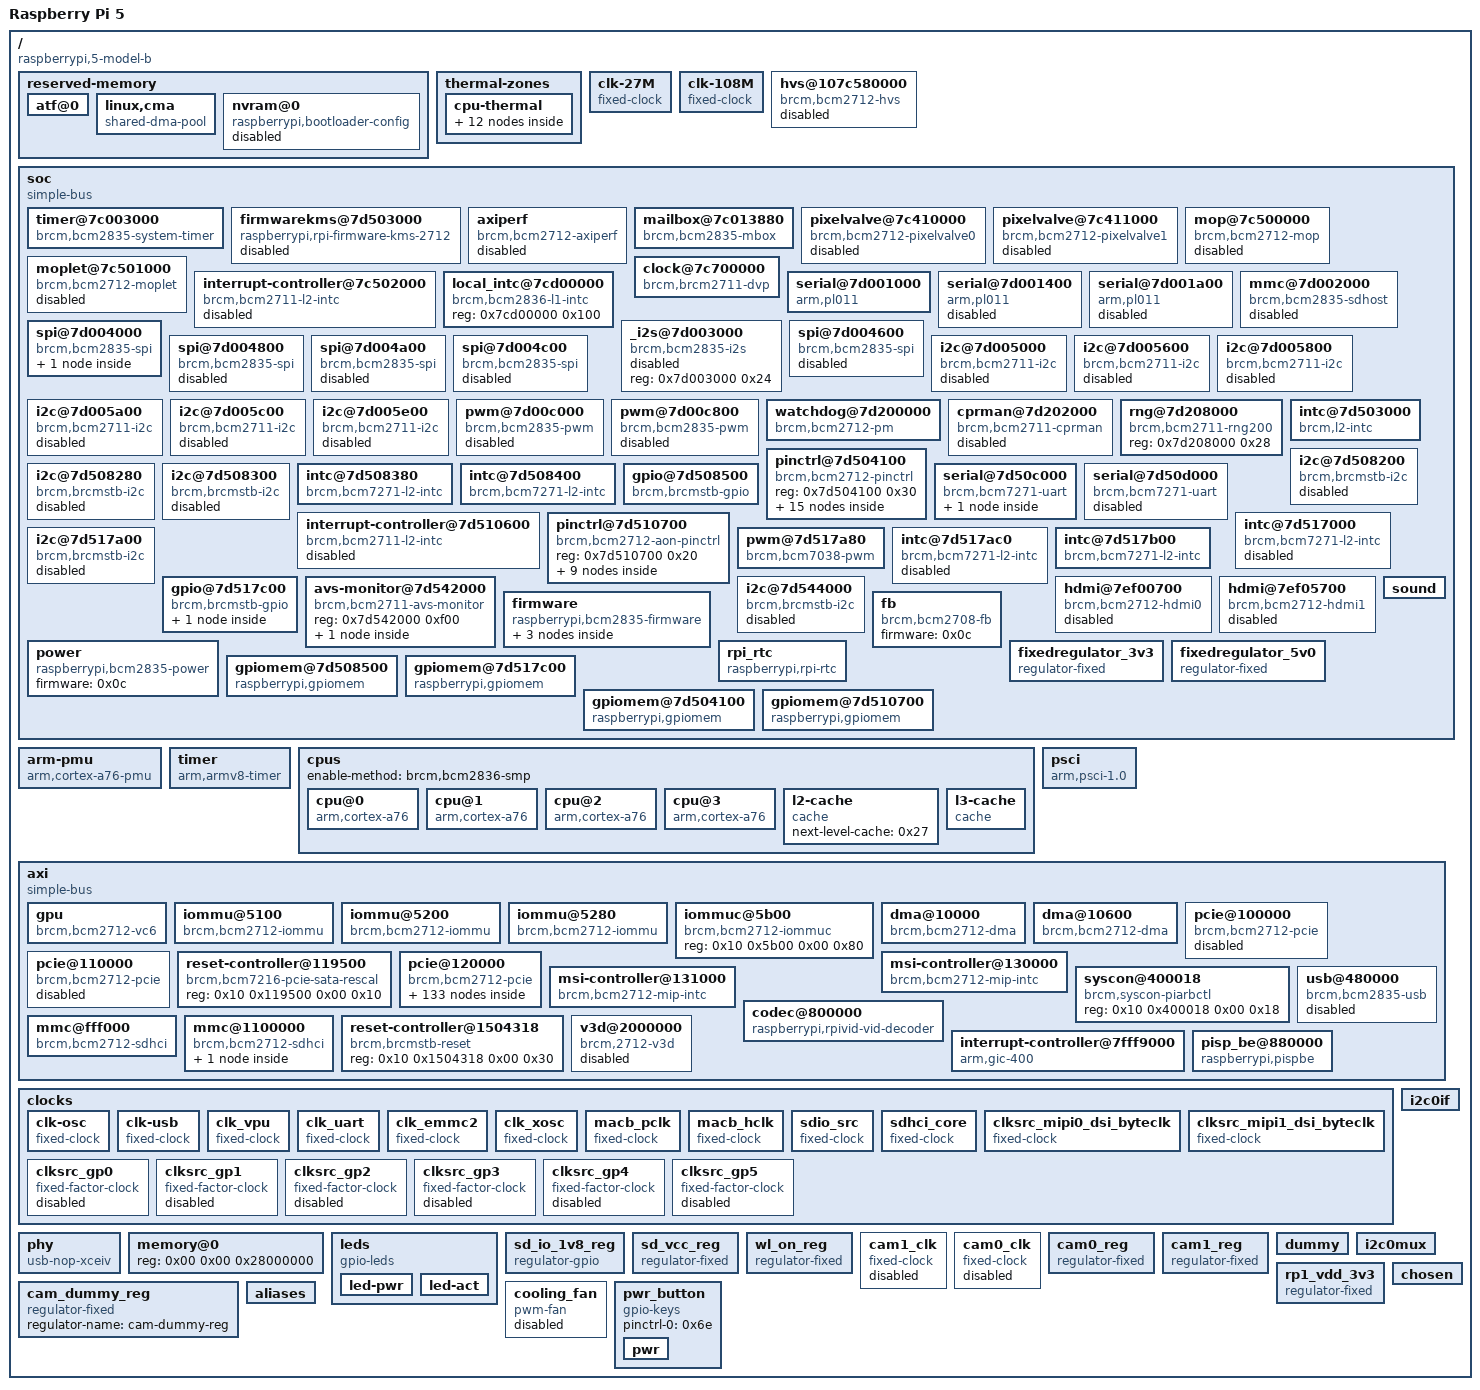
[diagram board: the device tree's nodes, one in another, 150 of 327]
/dts-v1/;

/ {
	compatible = "raspberrypi,5-model-b\0brcm,bcm2712";
	model = "Raspberry Pi 5";
	#address-cells = <0x02>;
	#size-cells = <0x01>;
	interrupt-parent = <0x01>;

	reserved-memory {
		#address-cells = <0x02>;
		#size-cells = <0x01>;
		ranges;
		phandle = <0x6f>;

		atf@0 {
			reg = <0x00 0x00 0x80000>;
			no-map;
		};

		linux,cma {
			compatible = "shared-dma-pool";
			size = <0x4000000>;
			reusable;
			linux,cma-default;
			alloc-ranges = <0x00 0x00 0x40000000>;
			phandle = <0x70>;
		};

		nvram@0 {
			compatible = "raspberrypi,bootloader-config\0nvmem-rmem";
			#address-cells = <0x01>;
			#size-cells = <0x01>;
			reg = <0x00 0x00 0x00>;
			no-map;
			status = "disabled";
			phandle = <0x71>;
		};
	};

	thermal-zones {

		cpu-thermal {
			polling-delay-passive = <0x7d0>;
			polling-delay = <0x3e8>;
			coefficients = <0xfffffdda 0x6ddd0>;
			thermal-sensors = <0x02>;
			phandle = <0x72>;

			trips {
				phandle = <0x73>;

				cpu-crit {
					temperature = <0x1adb0>;
					hysteresis = <0x00>;
					type = "critical";
					phandle = <0x08>;
				};

				cpu-tepid {
					temperature = <0xc350>;
					hysteresis = <0x1388>;
					type = "active";
					phandle = <0x03>;
				};

				cpu-warm {
					temperature = <0xea60>;
					hysteresis = <0x1388>;
					type = "active";
					phandle = <0x05>;
				};

				cpu-hot {
					temperature = <0x107ac>;
					hysteresis = <0x1388>;
					type = "active";
					phandle = <0x06>;
				};

				cpu-vhot {
					temperature = <0x124f8>;
					hysteresis = <0x1388>;
					type = "active";
					phandle = <0x07>;
				};
			};

			cooling-maps {
				phandle = <0x74>;

				tepid {
					trip = <0x03>;
					cooling-device = <0x04 0x01 0x01>;
				};

				warm {
					trip = <0x05>;
					cooling-device = <0x04 0x02 0x02>;
				};

				hot {
					trip = <0x06>;
					cooling-device = <0x04 0x03 0x03>;
				};

				vhot {
					trip = <0x07>;
					cooling-device = <0x04 0x04 0x04>;
				};

				melt {
					trip = <0x08>;
					cooling-device = <0x04 0x04 0x04>;
				};
			};
		};
	};

	clk-27M {
		#clock-cells = <0x00>;
		compatible = "fixed-clock";
		clock-frequency = <0x19bfcc0>;
		clock-output-names = "27MHz-clock";
		phandle = <0x1b>;
	};

	clk-108M {
		#clock-cells = <0x00>;
		compatible = "fixed-clock";
		clock-frequency = <0x66ff300>;
		clock-output-names = "108MHz-clock";
		phandle = <0x0d>;
	};

	hvs@107c580000 {
		compatible = "brcm,bcm2712-hvs";
		reg = <0x10 0x7c580000 0x1a000>;
		interrupt-parent = <0x09>;
		interrupts = <0x02 0x09 0x10>;
		interrupt-names = "ch0-eof\0ch1-eof\0ch2-eof";
		status = "disabled";
		clocks = <0x0a 0x04 0x0a 0x10>;
		clock-names = "core\0disp";
		phandle = <0x75>;
	};

	soc {
		compatible = "simple-bus";
		#address-cells = <0x01>;
		#size-cells = <0x01>;
		ranges = <0x7c000000 0x10 0x7c000000 0x4000000>;
		dma-ranges = <0xc0000000 0x00 0x00 0x40000000 0x7c000000 0x10 0x7c000000 0x4000000>;
		phandle = <0x76>;

		timer@7c003000 {
			compatible = "brcm,bcm2835-system-timer";
			reg = <0x7c003000 0x1000>;
			interrupts = <0x00 0x40 0x04 0x00 0x41 0x04 0x00 0x42 0x04 0x00 0x43 0x04>;
			clock-frequency = <0xf4240>;
			phandle = <0x77>;
		};

		firmwarekms@7d503000 {
			compatible = "raspberrypi,rpi-firmware-kms-2712";
			reg = <0x7d503000 0x18>;
			interrupt-parent = <0x0b>;
			interrupts = <0x13>;
			brcm,firmware = <0x0c>;
			status = "disabled";
			phandle = <0x78>;
		};

		axiperf {
			compatible = "brcm,bcm2712-axiperf";
			reg = <0x7c012800 0x100 0x7e000000 0x100>;
			firmware = <0x0c>;
			status = "disabled";
			phandle = <0x5d>;
		};

		mailbox@7c013880 {
			compatible = "brcm,bcm2835-mbox";
			reg = <0x7c013880 0x40>;
			interrupts = <0x00 0x21 0x04>;
			#mbox-cells = <0x00>;
			phandle = <0x21>;
		};

		pixelvalve@7c410000 {
			compatible = "brcm,bcm2712-pixelvalve0";
			reg = <0x7c410000 0x100>;
			interrupts = <0x00 0x65 0x04>;
			status = "disabled";
			phandle = <0x79>;
		};

		pixelvalve@7c411000 {
			compatible = "brcm,bcm2712-pixelvalve1";
			reg = <0x7c411000 0x100>;
			interrupts = <0x00 0x6e 0x04>;
			status = "disabled";
			phandle = <0x7a>;
		};

		mop@7c500000 {
			compatible = "brcm,bcm2712-mop";
			reg = <0x7c500000 0x28>;
			interrupt-parent = <0x09>;
			interrupts = <0x01>;
			status = "disabled";
			phandle = <0x7b>;
		};

		moplet@7c501000 {
			compatible = "brcm,bcm2712-moplet";
			reg = <0x7c501000 0x20>;
			interrupt-parent = <0x09>;
			interrupts = <0x00>;
			status = "disabled";
			phandle = <0x7c>;
		};

		interrupt-controller@7c502000 {
			compatible = "brcm,bcm2711-l2-intc\0brcm,l2-intc";
			reg = <0x7c502000 0x30>;
			interrupts = <0x00 0x61 0x04>;
			interrupt-controller;
			#interrupt-cells = <0x01>;
			status = "disabled";
			phandle = <0x09>;
		};

		clock@7c700000 {
			compatible = "brcm,brcm2711-dvp";
			reg = <0x7c700000 0x10>;
			clocks = <0x0d>;
			#clock-cells = <0x01>;
			#reset-cells = <0x01>;
			phandle = <0x1d>;
		};

		local_intc@7cd00000 {
			compatible = "brcm,bcm2836-l1-intc";
			reg = <0x7cd00000 0x100>;
			phandle = <0x7d>;
		};

		serial@7d001000 {
			compatible = "arm,pl011\0arm,primecell";
			reg = <0x7d001000 0x200>;
			interrupts = <0x00 0x79 0x04>;
			clocks = <0x0e 0x0f>;
			clock-names = "uartclk\0apb_pclk";
			arm,primecell-periphid = <0x241011>;
			status = "okay";
			phandle = <0x7e>;
		};

		serial@7d001400 {
			compatible = "arm,pl011\0arm,primecell";
			reg = <0x7d001400 0x200>;
			interrupts = <0x00 0x79 0x04>;
			clocks = <0x0e 0x0f>;
			clock-names = "uartclk\0apb_pclk";
			arm,primecell-periphid = <0x241011>;
			status = "disabled";
			phandle = <0x7f>;
		};

		serial@7d001a00 {
			compatible = "arm,pl011\0arm,primecell";
			reg = <0x7d001a00 0x200>;
			interrupts = <0x00 0x79 0x04>;
			clocks = <0x0e 0x0f>;
			clock-names = "uartclk\0apb_pclk";
			arm,primecell-periphid = <0x241011>;
			status = "disabled";
			phandle = <0x80>;
		};

		mmc@7d002000 {
			compatible = "brcm,bcm2835-sdhost";
			reg = <0x7d002000 0x100>;
			clocks = <0x0f>;
			status = "disabled";
			phandle = <0x81>;
		};

		_i2s@7d003000 {
			compatible = "brcm,bcm2835-i2s";
			reg = <0x7d003000 0x24>;
			status = "disabled";
			phandle = <0x82>;
		};

		spi@7d004000 {
			compatible = "brcm,bcm2835-spi";
			reg = <0x7d004000 0x200>;
			interrupts = <0x00 0x76 0x04>;
			clocks = <0x0f>;
			num-cs = <0x01>;
			#address-cells = <0x01>;
			#size-cells = <0x00>;
			status = "okay";
			dmas = <0x10 0x06 0x10 0x07>;
			dma-names = "tx\0rx";
			pinctrl-names = "default";
			cs-gpios = <0x11 0x01 0x01>;
			pinctrl-0 = <0x12 0x13>;
			phandle = <0x83>;

			spidev@0 {
				compatible = "spidev";
				reg = <0x00>;
				#address-cells = <0x01>;
				#size-cells = <0x00>;
				spi-max-frequency = <0x1312d00>;
				status = "okay";
				phandle = <0x84>;
			};
		};

		spi@7d004600 {
			compatible = "brcm,bcm2835-spi";
			reg = <0x7d004600 0x200>;
			interrupts = <0x00 0x76 0x04>;
			clocks = <0x0f>;
			#address-cells = <0x01>;
			#size-cells = <0x00>;
			status = "disabled";
			phandle = <0x85>;
		};

		spi@7d004800 {
			compatible = "brcm,bcm2835-spi";
			reg = <0x7d004800 0x200>;
			interrupts = <0x00 0x76 0x04>;
			clocks = <0x0f>;
			#address-cells = <0x01>;
			#size-cells = <0x00>;
			status = "disabled";
			phandle = <0x86>;
		};

		spi@7d004a00 {
			compatible = "brcm,bcm2835-spi";
			reg = <0x7d004a00 0x200>;
			interrupts = <0x00 0x76 0x04>;
			clocks = <0x0f>;
			#address-cells = <0x01>;
			#size-cells = <0x00>;
			status = "disabled";
			phandle = <0x87>;
		};

		spi@7d004c00 {
			compatible = "brcm,bcm2835-spi";
			reg = <0x7d004c00 0x200>;
			interrupts = <0x00 0x76 0x04>;
			clocks = <0x0f>;
			#address-cells = <0x01>;
			#size-cells = <0x00>;
			status = "disabled";
			phandle = <0x88>;
		};

		i2c@7d005000 {
			compatible = "brcm,bcm2711-i2c\0brcm,bcm2835-i2c";
			reg = <0x7d005000 0x20>;
			interrupts = <0x00 0x75 0x04>;
			clocks = <0x0f>;
			#address-cells = <0x01>;
			#size-cells = <0x00>;
			status = "disabled";
			phandle = <0x89>;
		};

		i2c@7d005600 {
			compatible = "brcm,bcm2711-i2c\0brcm,bcm2835-i2c";
			reg = <0x7d005600 0x20>;
			interrupts = <0x00 0x75 0x04>;
			clocks = <0x0f>;
			#address-cells = <0x01>;
			#size-cells = <0x00>;
			status = "disabled";
			clock-frequency = <0x61a80>;
			pinctrl-0 = <0x14>;
			pinctrl-names = "default";
			phandle = <0x8a>;
		};

		i2c@7d005800 {
			compatible = "brcm,bcm2711-i2c\0brcm,bcm2835-i2c";
			reg = <0x7d005800 0x20>;
			interrupts = <0x00 0x75 0x04>;
			clocks = <0x0f>;
			#address-cells = <0x01>;
			#size-cells = <0x00>;
			status = "disabled";
			phandle = <0x8b>;
		};

		i2c@7d005a00 {
			compatible = "brcm,bcm2711-i2c\0brcm,bcm2835-i2c";
			reg = <0x7d005a00 0x20>;
			interrupts = <0x00 0x75 0x04>;
			clocks = <0x0f>;
			#address-cells = <0x01>;
			#size-cells = <0x00>;
			status = "disabled";
			phandle = <0x8c>;
		};

		i2c@7d005c00 {
			compatible = "brcm,bcm2711-i2c\0brcm,bcm2835-i2c";
			reg = <0x7d005c00 0x20>;
			interrupts = <0x00 0x75 0x04>;
			clocks = <0x0f>;
			#address-cells = <0x01>;
			#size-cells = <0x00>;
			status = "disabled";
			phandle = <0x8d>;
		};

		i2c@7d005e00 {
			compatible = "brcm,bcm2711-i2c\0brcm,bcm2835-i2c";
			reg = <0x7d005e00 0x20>;
			interrupts = <0x00 0x75 0x04>;
			clocks = <0x0f>;
			#address-cells = <0x01>;
			#size-cells = <0x00>;
			status = "disabled";
			phandle = <0x8e>;
		};

		pwm@7d00c000 {
			compatible = "brcm,bcm2835-pwm";
			reg = <0x7d00c000 0x28>;
			assigned-clock-rates = <0x989680>;
			#pwm-cells = <0x03>;
			status = "disabled";
			phandle = <0x8f>;
		};

		pwm@7d00c800 {
			compatible = "brcm,bcm2835-pwm";
			reg = <0x7d00c800 0x28>;
			assigned-clock-rates = <0x989680>;
			#pwm-cells = <0x03>;
			status = "disabled";
			phandle = <0x90>;
		};

		watchdog@7d200000 {
			compatible = "brcm,bcm2712-pm";
			reg = <0x7d200000 0x308>;
			reg-names = "pm";
			#power-domain-cells = <0x01>;
			#reset-cells = <0x01>;
			clock-names = "v3d\0peri_image\0h264\0isp";
			system-power-controller;
			phandle = <0x5b>;
		};

		cprman@7d202000 {
			compatible = "brcm,bcm2711-cprman";
			reg = <0x7d202000 0x2000>;
			#clock-cells = <0x01>;
			clocks = <0x15>;
			status = "disabled";
			phandle = <0x91>;
		};

		rng@7d208000 {
			compatible = "brcm,bcm2711-rng200";
			reg = <0x7d208000 0x28>;
			status = "okay";
			phandle = <0x68>;
		};

		intc@7d503000 {
			compatible = "brcm,l2-intc";
			reg = <0x7d503000 0x18>;
			interrupts = <0x00 0xee 0x04>;
			interrupt-controller;
			#interrupt-cells = <0x01>;
			phandle = <0x0b>;
		};

		pinctrl@7d504100 {
			compatible = "brcm,bcm2712-pinctrl";
			reg = <0x7d504100 0x30>;
			phandle = <0x92>;

			uarta_24_pins {
				phandle = <0x18>;

				pin_rts {
					function = "uart0";
					pins = "gpio24";
					bias-disable;
				};

				pin_cts {
					function = "uart0";
					pins = "gpio25";
					bias-pull-up;
				};

				pin_txd {
					function = "uart0";
					pins = "gpio26";
					bias-disable;
				};

				pin_rxd {
					function = "uart0";
					pins = "gpio27";
					bias-pull-up;
				};
			};

			sdio2_30_pins {
				phandle = <0x59>;

				pin_clk {
					function = "sd2";
					pins = "gpio30";
					bias-disable;
				};

				pin_cmd {
					function = "sd2";
					pins = "gpio31";
					bias-pull-up;
				};

				pins_dat {
					function = "sd2";
					pins = "gpio32\0gpio33\0gpio34\0gpio35";
					bias-pull-up;
				};
			};

			pwr_button_pins {
				function = "gpio";
				pins = "gpio20";
				bias-pull-up;
				phandle = <0x6e>;
			};

			wl_on_pins {
				function = "gpio";
				pins = "gpio28";
				phandle = <0x5c>;
			};

			bt_shutdown_pins {
				function = "gpio";
				pins = "gpio29";
				phandle = <0x19>;
			};

			emmc_sd_pulls {
				pins = "emmc_cmd\0emmc_dat0\0emmc_dat1\0emmc_dat2\0emmc_dat3";
				bias-pull-up;
				phandle = <0x54>;
			};

			spi10_gpio2 {
				function = "vc_spi0";
				pins = "gpio2\0gpio3\0gpio4";
				bias-disable;
				phandle = <0x12>;
			};

			spi10_cs_gpio1 {
				function = "gpio";
				pins = "gpio1";
				bias-pull-up;
				phandle = <0x13>;
			};
		};

		i2c@7d508200 {
			compatible = "brcm,brcmstb-i2c";
			reg = <0x7d508200 0x58>;
			interrupt-parent = <0x16>;
			interrupts = <0x01>;
			clock-frequency = <0x17cdc>;
			#address-cells = <0x01>;
			#size-cells = <0x00>;
			status = "disabled";
			phandle = <0x1f>;
		};

		i2c@7d508280 {
			compatible = "brcm,brcmstb-i2c";
			reg = <0x7d508280 0x58>;
			interrupt-parent = <0x16>;
			interrupts = <0x02>;
			clock-frequency = <0x17cdc>;
			#address-cells = <0x01>;
			#size-cells = <0x00>;
			status = "disabled";
			phandle = <0x20>;
		};

		i2c@7d508300 {
			compatible = "brcm,brcmstb-i2c";
			reg = <0x7d508300 0x58>;
			interrupt-parent = <0x16>;
			interrupts = <0x00>;
			clock-frequency = <0x30d40>;
			#address-cells = <0x01>;
			#size-cells = <0x00>;
			status = "disabled";
			phandle = <0x93>;
		};

		intc@7d508380 {
			compatible = "brcm,bcm7271-l2-intc";
			reg = <0x7d508380 0x10>;
			interrupts = <0x00 0xf2 0x04>;
			interrupt-controller;
			#interrupt-cells = <0x01>;
			phandle = <0x16>;
		};

		intc@7d508400 {
			compatible = "brcm,bcm7271-l2-intc";
			reg = <0x7d508400 0x10>;
			interrupts = <0x00 0xf4 0x04>;
			interrupt-controller;
			#interrupt-cells = <0x01>;
			phandle = <0x17>;
		};

		gpio@7d508500 {
			compatible = "brcm,brcmstb-gpio";
			reg = <0x7d508500 0x40>;
			interrupt-parent = <0x17>;
			interrupts = <0x00>;
			gpio-controller;
			#gpio-cells = <0x02>;
			interrupt-controller;
			#interrupt-cells = <0x02>;
			brcm,gpio-bank-widths = <0x20 0x04>;
			brcm,gpio-direct;
			gpio-line-names = "-\02712_BOOT_CS_N\02712_BOOT_MISO\02712_BOOT_MOSI\02712_BOOT_SCLK\0-\0-\0-\0-\0-\0-\0-\0-\0-\0PCIE_SDA\0PCIE_SCL\0-\0-\0-\0-\0PWR_GPIO\02712_G21_FS\0-\0-\0BT_RTS\0BT_CTS\0BT_TXD\0BT_RXD\0WL_ON\0BT_ON\0WIFI_SDIO_CLK\0WIFI_SDIO_CMD\0WIFI_SDIO_D0\0WIFI_SDIO_D1\0WIFI_SDIO_D2\0WIFI_SDIO_D3";
			phandle = <0x11>;
		};

		serial@7d50c000 {
			compatible = "brcm,bcm7271-uart";
			reg = <0x7d50c000 0x20>;
			reg-names = "uart";
			reg-shift = <0x02>;
			reg-io-width = <0x04>;
			interrupts = <0x00 0x114 0x04>;
			skip-init;
			status = "okay";
			uart-has-rtscts;
			auto-flow-control;
			clock-frequency = <0x5b8d800>;
			pinctrl-0 = <0x18 0x19>;
			pinctrl-names = "default";
			phandle = <0x94>;

			bluetooth {
				compatible = "brcm,bcm43438-bt";
				max-speed = <0x2dc6c0>;
				shutdown-gpios = <0x11 0x1d 0x00>;
				local-bd-address = [00 00 00 00 00 00];
				phandle = <0x5e>;
			};
		};

		serial@7d50d000 {
			compatible = "brcm,bcm7271-uart";
			reg = <0x7d50d000 0x20>;
			reg-names = "uart";
			reg-shift = <0x02>;
			reg-io-width = <0x04>;
			interrupts = <0x00 0x115 0x04>;
			skip-init;
			status = "disabled";
			phandle = <0x95>;
		};

		interrupt-controller@7d510600 {
			compatible = "brcm,bcm2711-l2-intc\0brcm,l2-intc";
			reg = <0x7d510600 0x30>;
			interrupts = <0x00 0xef 0x04>;
			interrupt-controller;
			#interrupt-cells = <0x01>;
			status = "disabled";
			phandle = <0x1e>;
		};

		pinctrl@7d510700 {
			compatible = "brcm,bcm2712-aon-pinctrl";
			reg = <0x7d510700 0x20>;
			phandle = <0x96>;

			i2c3_m4_agpio0_pins {
				function = "vc_i2c3";
				pins = "aon_gpio0\0aon_gpio1";
				bias-pull-up;
				phandle = <0x14>;
			};

			bsc_m1_agpio13_pins {
				function = "bsc_m1";
				pins = "aon_gpio13\0aon_gpio14";
				bias-pull-up;
				phandle = <0x97>;
			};

			bsc_pmu_sgpio4_pins {
				function = "avs_pmu_bsc";
				pins = "aon_sgpio4\0aon_sgpio5";
				phandle = <0x98>;
			};

			bsc_m2_sgpio4_pins {
				function = "bsc_m2";
				pins = "aon_sgpio4\0aon_sgpio5";
				phandle = <0x99>;
			};

			pwm_aon_agpio1_pins {
				function = "aon_pwm";
				pins = "aon_gpio1\0aon_gpio2";
				phandle = <0x9a>;
			};

			pwm_aon_agpio4_pins {
				function = "vc_pwm0";
				pins = "aon_gpio4\0aon_gpio5";
				phandle = <0x9b>;
			};

			pwm_aon_agpio7_pins {
				function = "aon_pwm";
				pins = "aon_gpio7\0aon_gpio9";
				phandle = <0x9c>;
			};

			emmc_aon_cd_pins {
				function = "sd_card_g";
				pins = "aon_gpio5";
				bias-pull-up;
				phandle = <0x55>;
			};

			aon_pwm_1pin {
				function = "aon_pwm";
				pins = "aon_gpio9";
				phandle = <0x9d>;
			};
		};

		intc@7d517000 {
			compatible = "brcm,bcm7271-l2-intc";
			reg = <0x7d517000 0x10>;
			interrupts = <0x00 0xf7 0x04>;
			interrupt-controller;
			#interrupt-cells = <0x01>;
			status = "disabled";
		};

		i2c@7d517a00 {
			compatible = "brcm,brcmstb-i2c";
			reg = <0x7d517a00 0x58>;
			interrupt-parent = <0x1a>;
			interrupts = <0x00>;
			clock-frequency = <0x30d40>;
			#address-cells = <0x01>;
			#size-cells = <0x00>;
			status = "disabled";
			phandle = <0x9e>;
		};

		pwm@7d517a80 {
			compatible = "brcm,bcm7038-pwm";
			reg = <0x7d517a80 0x28>;
			#pwm-cells = <0x03>;
			clocks = <0x1b>;
			phandle = <0x9f>;
		};

		intc@7d517ac0 {
			compatible = "brcm,bcm7271-l2-intc";
			reg = <0x7d517ac0 0x10>;
			interrupts = <0x00 0xf5 0x04>;
			interrupt-controller;
			#interrupt-cells = <0x01>;
			status = "disabled";
			phandle = <0x1c>;
		};

		intc@7d517b00 {
			compatible = "brcm,bcm7271-l2-intc";
			reg = <0x7d517b00 0x10>;
			interrupts = <0x00 0xf3 0x04>;
			interrupt-controller;
			#interrupt-cells = <0x01>;
			phandle = <0x1a>;
		};

		gpio@7d517c00 {
			compatible = "brcm,brcmstb-gpio";
			reg = <0x7d517c00 0x40>;
			interrupt-parent = <0x1c>;
			interrupts = <0x00>;
			gpio-controller;
			#gpio-cells = <0x02>;
			#interrupt-cells = <0x02>;
			brcm,gpio-bank-widths = <0x11 0x06>;
			brcm,gpio-direct;
			gpio-line-names = "RP1_SDA\0RP1_SCL\0RP1_RUN\0SD_IOVDD_SEL\0SD_PWR_ON\0SD_CDET_N\0SD_FLG_N\0-\02712_WAKE\02712_STAT_LED\0-\0-\0PMIC_INT\0UART_TX_FS\0UART_RX_FS\0-\0-\0\0\0\0\0\0\0\0\0\0\0\0\0\0\0\0HDMI0_SCL\0HDMI0_SDA\0HDMI1_SCL\0HDMI1_SDA\0PMIC_SCL\0PMIC_SDA";
			phandle = <0x58>;

			rp1_run_hog {
				gpio-hog;
				gpios = <0x02 0x00>;
				output-high;
				line-name = "RP1 RUN pin";
			};
		};

		avs-monitor@7d542000 {
			compatible = "brcm,bcm2711-avs-monitor\0syscon\0simple-mfd";
			reg = <0x7d542000 0xf00>;
			status = "okay";
			phandle = <0xa0>;

			thermal {
				compatible = "brcm,bcm2711-thermal";
				#thermal-sensor-cells = <0x00>;
				phandle = <0x02>;
			};
		};

		i2c@7d544000 {
			compatible = "brcm,brcmstb-i2c";
			reg = <0x7d544000 0x58>;
			interrupt-parent = <0x1a>;
			interrupts = <0x01>;
			clock-frequency = <0x30d40>;
			status = "disabled";
			phandle = <0xa1>;
		};

		hdmi@7ef00700 {
			compatible = "brcm,bcm2712-hdmi0";
			reg = <0x7c701400 0x300 0x7c701000 0x200 0x7c701d00 0x300 0x7c702000 0x80 0x7c703800 0x200 0x7c704000 0x800 0x7c700100 0x80 0x7d510800 0x100 0x7c720000 0x100>;
			reg-names = "hdmi\0dvp\0phy\0rm\0packet\0metadata\0csc\0cec\0hd";
			resets = <0x1d 0x01>;
			interrupt-parent = <0x1e>;
			interrupts = <0x01 0x02 0x03 0x07 0x08>;
			interrupt-names = "cec-tx\0cec-rx\0cec-low\0hpd-connected\0hpd-removed";
			ddc = <0x1f>;
			dmas = <0x10 0x41fa000a>;
			dma-names = "audio-rx";
			status = "disabled";
			clocks = <0x0a 0x0d 0x0a 0x0e 0x1d 0x00 0x1b>;
			clock-names = "hdmi\0bvb\0audio\0cec";
			phandle = <0xa2>;
		};

		hdmi@7ef05700 {
			compatible = "brcm,bcm2712-hdmi1";
			reg = <0x7c706400 0x300 0x7c706000 0x200 0x7c706d00 0x300 0x7c707000 0x80 0x7c708800 0x200 0x7c709000 0x800 0x7c700180 0x80 0x7d511000 0x100 0x7c720000 0x100>;
			reg-names = "hdmi\0dvp\0phy\0rm\0packet\0metadata\0csc\0cec\0hd";
			ddc = <0x20>;
			resets = <0x1d 0x02>;
			interrupt-parent = <0x1e>;
			interrupts = <0x0b 0x0c 0x0d 0x0e 0x0f>;
			interrupt-names = "cec-tx\0cec-rx\0cec-low\0hpd-connected\0hpd-removed";
			dmas = <0x10 0x41fa0011>;
			dma-names = "audio-rx";
			status = "disabled";
			clocks = <0x0a 0x0d 0x0a 0x0e 0x1d 0x01 0x1b>;
			clock-names = "hdmi\0bvb\0audio\0cec";
			phandle = <0xa3>;
		};

		sound {
			phandle = <0xa4>;
		};

		firmware {
			compatible = "raspberrypi,bcm2835-firmware\0simple-mfd";
			#address-cells = <0x01>;
			#size-cells = <0x01>;
			mboxes = <0x21>;
			dma-ranges;
			phandle = <0x0c>;

			clocks {
				compatible = "raspberrypi,firmware-clocks";
				#clock-cells = <0x01>;
				phandle = <0x0a>;
			};

			reset {
				compatible = "raspberrypi,firmware-reset";
				#reset-cells = <0x01>;
				phandle = <0xa5>;
			};

			vcio {
				compatible = "raspberrypi,vcio";
				phandle = <0xa6>;
			};
		};

		power {
			compatible = "raspberrypi,bcm2835-power";
			firmware = <0x0c>;
			#power-domain-cells = <0x01>;
			phandle = <0x51>;
		};

		fb {
			compatible = "brcm,bcm2708-fb";
			firmware = <0x0c>;
			status = "okay";
			phandle = <0xa7>;
		};

		rpi_rtc {
			compatible = "raspberrypi,rpi-rtc";
			firmware = <0x0c>;
			status = "okay";
			trickle-charge-microvolt = <0x00>;
			phandle = <0x69>;
		};

		fixedregulator_3v3 {
			compatible = "regulator-fixed";
			regulator-always-on;
			regulator-max-microvolt = <0x325aa0>;
			regulator-min-microvolt = <0x325aa0>;
			regulator-name = "3v3";
			phandle = <0xa8>;
		};

		fixedregulator_5v0 {
			compatible = "regulator-fixed";
			regulator-always-on;
			regulator-max-microvolt = <0x4c4b40>;
			regulator-min-microvolt = <0x4c4b40>;
			regulator-name = "5v0";
			phandle = <0xa9>;
		};

		gpiomem@7d508500 {
			compatible = "raspberrypi,gpiomem";
			reg = <0x7d508500 0x40>;
			chardev-name = "gpiomem1";
		};

		gpiomem@7d517c00 {
			compatible = "raspberrypi,gpiomem";
			reg = <0x7d517c00 0x40>;
			chardev-name = "gpiomem2";
		};

		gpiomem@7d504100 {
			compatible = "raspberrypi,gpiomem";
			reg = <0x7d504100 0x20>;
			chardev-name = "gpiomem3";
		};

		gpiomem@7d510700 {
			compatible = "raspberrypi,gpiomem";
			reg = <0x7d510700 0x20>;
			chardev-name = "gpiomem4";
		};
	};

	arm-pmu {
		compatible = "arm,cortex-a76-pmu";
		interrupts = <0x00 0x10 0x04 0x00 0x11 0x04 0x00 0x12 0x04 0x00 0x13 0x04>;
		interrupt-affinity = <0x22 0x23 0x24 0x25>;
	};

	timer {
		compatible = "arm,armv8-timer";
		interrupts = <0x01 0x0d 0xf08 0x01 0x0e 0xf08 0x01 0x0b 0xf08 0x01 0x0a 0xf08>;
		arm,cpu-registers-not-fw-configured;
	};

	cpus {
		#address-cells = <0x01>;
		#size-cells = <0x00>;
		enable-method = "brcm,bcm2836-smp";
		phandle = <0xaa>;

		cpu@0 {
			device_type = "cpu";
			compatible = "arm,cortex-a76";
			reg = <0x00>;
			enable-method = "psci";
			next-level-cache = <0x26>;
			phandle = <0x22>;
		};

		cpu@1 {
			device_type = "cpu";
			compatible = "arm,cortex-a76";
			reg = <0x100>;
			enable-method = "psci";
			next-level-cache = <0x26>;
			phandle = <0x23>;
		};

		cpu@2 {
			device_type = "cpu";
			compatible = "arm,cortex-a76";
			reg = <0x200>;
			enable-method = "psci";
			next-level-cache = <0x26>;
			phandle = <0x24>;
		};

		cpu@3 {
			device_type = "cpu";
			compatible = "arm,cortex-a76";
			reg = <0x300>;
			enable-method = "psci";
			next-level-cache = <0x26>;
			phandle = <0x25>;
		};

		l2-cache {
			compatible = "cache";
			next-level-cache = <0x27>;
			phandle = <0x26>;
		};

		l3-cache {
			compatible = "cache";
			phandle = <0x27>;
		};
	};

	psci {
		method = "smc";
		compatible = "arm,psci-1.0\0arm,psci-0.2\0arm,psci";
		cpu_on = <0xc4000003>;
		cpu_suspend = <0xc4000001>;
		cpu_off = <0x84000002>;
	};

	axi {
		compatible = "simple-bus";
		#address-cells = <0x02>;
		#size-cells = <0x02>;
		ranges = <0x00 0x00 0x00 0x00 0x10 0x00 0x10 0x00 0x10 0x00 0x01 0x00 0x14 0x00 0x14 0x00 0x04 0x00 0x18 0x00 0x18 0x00 0x04 0x00 0x1c 0x00 0x1c 0x00 0x04 0x00>;
		dma-ranges = <0x00 0x00 0x00 0x00 0x10 0x00 0x10 0x00 0x10 0x00 0x01 0x00 0x14 0x00 0x14 0x00 0x04 0x00 0x18 0x00 0x18 0x00 0x04 0x00 0x1c 0x00 0x1c 0x00 0x04 0x00>;
		phandle = <0xab>;

		gpu {
			compatible = "brcm,bcm2712-vc6";
			phandle = <0xac>;
		};

		iommu@5100 {
			compatible = "brcm,bcm2712-iommu";
			reg = <0x10 0x5100 0x00 0x80>;
			cache = <0x28>;
			#iommu-cells = <0x00>;
			phandle = <0x52>;
		};

		iommu@5200 {
			compatible = "brcm,bcm2712-iommu";
			reg = <0x10 0x5200 0x00 0x80>;
			cache = <0x28>;
			#iommu-cells = <0x00>;
			#interconnect-cells = <0x00>;
			phandle = <0xad>;
		};

		iommu@5280 {
			compatible = "brcm,bcm2712-iommu";
			reg = <0x10 0x5280 0x00 0x80>;
			cache = <0x28>;
			#iommu-cells = <0x00>;
			dma-iova-offset = <0x10 0x00>;
			phandle = <0x49>;
		};

		iommuc@5b00 {
			compatible = "brcm,bcm2712-iommuc";
			reg = <0x10 0x5b00 0x00 0x80>;
			phandle = <0x28>;
		};

		dma@10000 {
			compatible = "brcm,bcm2712-dma";
			reg = <0x10 0x10000 0x00 0x600>;
			interrupts = <0x00 0x50 0x04 0x00 0x51 0x04 0x00 0x52 0x04 0x00 0x53 0x04 0x00 0x54 0x04 0x00 0x55 0x04>;
			interrupt-names = "dma0\0dma1\0dma2\0dma3\0dma4\0dma5";
			#dma-cells = <0x01>;
			brcm,dma-channel-mask = <0x3f>;
			phandle = <0xae>;
		};

		dma@10600 {
			compatible = "brcm,bcm2712-dma";
			reg = <0x10 0x10600 0x00 0x600>;
			interrupts = <0x00 0x56 0x04 0x00 0x57 0x04 0x00 0x58 0x04 0x00 0x59 0x04 0x00 0x5a 0x04 0x00 0x5b 0x04>;
			interrupt-names = "dma6\0dma7\0dma8\0dma9\0dma10\0dma11";
			#dma-cells = <0x01>;
			brcm,dma-channel-mask = <0x7c0>;
			phandle = <0x10>;
		};

		pcie@100000 {
			compatible = "brcm,bcm2712-pcie";
			reg = <0x10 0x100000 0x00 0x9310>;
			device_type = "pci";
			max-link-speed = <0x02>;
			#address-cells = <0x03>;
			#interrupt-cells = <0x01>;
			#size-cells = <0x02>;
			interrupt-parent = <0x01>;
			interrupts = <0x00 0xd5 0x04 0x00 0xd6 0x04>;
			interrupt-names = "pcie\0msi";
			interrupt-map-mask = <0x00 0x00 0x00 0x07>;
			interrupt-map = <0x00 0x00 0x00 0x01 0x01 0x00 0xd1 0x04 0x00 0x00 0x00 0x02 0x01 0x00 0xd2 0x04 0x00 0x00 0x00 0x03 0x01 0x00 0xd3 0x04 0x00 0x00 0x00 0x04 0x01 0x00 0xd4 0x04>;
			resets = <0x29 0x05 0x29 0x2a 0x2a>;
			reset-names = "swinit\0bridge\0rescal";
			msi-controller;
			msi-parent = <0x2b>;
			ranges = <0x2000000 0x00 0x00 0x17 0x00 0x00 0xfffffffc 0x43000000 0x04 0x00 0x14 0x00 0x03 0x00>;
			dma-ranges = <0x43000000 0x10 0x00 0x00 0x00 0x10 0x00>;
			status = "disabled";
			phandle = <0x2b>;
		};

		pcie@110000 {
			compatible = "brcm,bcm2712-pcie";
			reg = <0x10 0x110000 0x00 0x9310>;
			device_type = "pci";
			max-link-speed = <0x02>;
			#address-cells = <0x03>;
			#interrupt-cells = <0x01>;
			#size-cells = <0x02>;
			interrupt-parent = <0x01>;
			interrupts = <0x00 0xdf 0x04 0x00 0xe0 0x04>;
			interrupt-names = "pcie\0msi";
			interrupt-map-mask = <0x00 0x00 0x00 0x07>;
			interrupt-map = <0x00 0x00 0x00 0x01 0x01 0x00 0xdb 0x04 0x00 0x00 0x00 0x02 0x01 0x00 0xdc 0x04 0x00 0x00 0x00 0x03 0x01 0x00 0xdd 0x04 0x00 0x00 0x00 0x04 0x01 0x00 0xde 0x04>;
			resets = <0x29 0x07 0x29 0x2b 0x2a>;
			reset-names = "swinit\0bridge\0rescal";
			msi-controller;
			msi-parent = <0x2c>;
			ranges = <0x2000000 0x00 0x00 0x1b 0x00 0x00 0xfffffffc 0x43000000 0x04 0x00 0x18 0x00 0x03 0x00>;
			dma-ranges = <0x3000000 0x10 0x00 0x00 0x00 0x10 0x00>;
			brcm,enable-l1ss;
			status = "disabled";
			phandle = <0x67>;
		};

		reset-controller@119500 {
			compatible = "brcm,bcm7216-pcie-sata-rescal";
			reg = <0x10 0x119500 0x00 0x10>;
			#reset-cells = <0x00>;
			phandle = <0x2a>;
		};

		pcie@120000 {
			compatible = "brcm,bcm2712-pcie";
			reg = <0x10 0x120000 0x00 0x9310>;
			device_type = "pci";
			max-link-speed = <0x02>;
			#address-cells = <0x03>;
			#interrupt-cells = <0x01>;
			#size-cells = <0x02>;
			interrupt-parent = <0x01>;
			interrupts = <0x00 0xe9 0x04 0x00 0xea 0x04>;
			interrupt-names = "pcie\0msi";
			interrupt-map-mask = <0x00 0x00 0x00 0x07>;
			interrupt-map = <0x00 0x00 0x00 0x01 0x01 0x00 0xe5 0x04 0x00 0x00 0x00 0x02 0x01 0x00 0xe6 0x04 0x00 0x00 0x00 0x03 0x01 0x00 0xe7 0x04 0x00 0x00 0x00 0x04 0x01 0x00 0xe8 0x04>;
			resets = <0x29 0x20 0x29 0x2c 0x2a>;
			reset-names = "swinit\0bridge\0rescal";
			msi-controller;
			msi-parent = <0x2d>;
			ranges = <0x2000000 0x00 0x00 0x1f 0x00 0x00 0xfffffffc 0x43000000 0x04 0x00 0x1c 0x00 0x03 0x00>;
			dma-ranges = <0x2000000 0x00 0x00 0x1f 0x00 0x00 0x400000 0x43000000 0x10 0x00 0x00 0x00 0x10 0x00>;
			brcm,enable-l1ss;
			status = "okay";
			brcm,enable-mps-rcb;
			brcm,vdm-qos-map = <0xbbaa9888>;
			aspm-no-l0s;
			phandle = <0xaf>;

			rp1 {
				compatible = "brcm,rp1-simple-bus";
				#address-cells = <0x02>;
				#size-cells = <0x02>;
				#interrupt-cells = <0x02>;
				interrupt-controller;
				interrupt-parent = <0x2e>;
				ranges = <0xc0 0x40000000 0x2000000 0x00 0x00 0x00 0x400000>;
				dma-ranges = <0x10 0x00 0x43000000 0x10 0x00 0x10 0x00 0xc0 0x40000000 0x2000000 0x00 0x00 0x00 0x400000 0x00 0x00 0x2000000 0x10 0x00 0x10 0x00>;
				phandle = <0x2e>;

				clocks@18000 {
					compatible = "raspberrypi,rp1-clocks";
					#clock-cells = <0x01>;
					reg = <0xc0 0x40018000 0x00 0x10038>;
					clocks = <0x2f>;
					assigned-clocks = <0x30 0x00 0x30 0x01 0x30 0x03 0x30 0x09 0x30 0x04 0x30 0x0a 0x30 0x0c 0x30 0x06 0x30 0x0d 0x30 0x1f 0x30 0x20 0x30 0x1d>;
					assigned-clock-rates = <0x3b9aca00 0x5b8d8000 0xbebc200 0x7735940 0x3a98000 0xb71b000 0xbebc200 0x5f5e100 0x2faf080 0xf4240 0xbebc200 0x2faf080>;
					phandle = <0x30>;
				};

				serial@30000 {
					compatible = "arm,pl011-axi";
					reg = <0xc0 0x40030000 0x00 0x100>;
					interrupts = <0x19 0x04>;
					clocks = <0x30 0x0f 0x30 0x06>;
					clock-names = "uartclk\0apb_pclk";
					dmas = <0x31 0x1a 0x31 0x19>;
					dma-names = "tx\0rx";
					pinctrl-names = "default";
					arm,primecell-periphid = <0x541011>;
					uart-has-rtscts;
					cts-event-workaround;
					skip-init;
					status = "disabled";
					pinctrl-0 = <0x32>;
					phandle = <0x61>;
				};

				serial@34000 {
					compatible = "arm,pl011-axi";
					reg = <0xc0 0x40034000 0x00 0x100>;
					interrupts = <0x2a 0x04>;
					clocks = <0x30 0x0f 0x30 0x06>;
					clock-names = "uartclk\0apb_pclk";
					pinctrl-names = "default";
					arm,primecell-periphid = <0x541011>;
					uart-has-rtscts;
					cts-event-workaround;
					skip-init;
					status = "disabled";
					phandle = <0xb0>;
				};

				serial@38000 {
					compatible = "arm,pl011-axi";
					reg = <0xc0 0x40038000 0x00 0x100>;
					interrupts = <0x2b 0x04>;
					clocks = <0x30 0x0f 0x30 0x06>;
					clock-names = "uartclk\0apb_pclk";
					pinctrl-names = "default";
					arm,primecell-periphid = <0x541011>;
					uart-has-rtscts;
					cts-event-workaround;
					skip-init;
					status = "disabled";
					phandle = <0xb1>;
				};

				serial@3c000 {
					compatible = "arm,pl011-axi";
					reg = <0xc0 0x4003c000 0x00 0x100>;
					interrupts = <0x2c 0x04>;
					clocks = <0x30 0x0f 0x30 0x06>;
					clock-names = "uartclk\0apb_pclk";
					pinctrl-names = "default";
					arm,primecell-periphid = <0x541011>;
					uart-has-rtscts;
					cts-event-workaround;
					skip-init;
					status = "disabled";
					phandle = <0xb2>;
				};

				serial@40000 {
					compatible = "arm,pl011-axi";
					reg = <0xc0 0x40040000 0x00 0x100>;
					interrupts = <0x2d 0x04>;
					clocks = <0x30 0x0f 0x30 0x06>;
					clock-names = "uartclk\0apb_pclk";
					pinctrl-names = "default";
					arm,primecell-periphid = <0x541011>;
					uart-has-rtscts;
					cts-event-workaround;
					skip-init;
					status = "disabled";
					phandle = <0xb3>;
				};

				serial@44000 {
					compatible = "arm,pl011-axi";
					reg = <0xc0 0x40044000 0x00 0x100>;
					interrupts = <0x2e 0x04>;
					clocks = <0x30 0x0f 0x30 0x06>;
					clock-names = "uartclk\0apb_pclk";
					pinctrl-names = "default";
					arm,primecell-periphid = <0x541011>;
					uart-has-rtscts;
					cts-event-workaround;
					skip-init;
					status = "disabled";
					phandle = <0xb4>;
				};

				spi@4c000 {
					reg = <0xc0 0x4004c000 0x00 0x130>;
					compatible = "snps,dw-apb-ssi";
					interrupts = <0x38 0x04>;
					clocks = <0x30 0x0c>;
					clock-names = "ssi_clk";
					#address-cells = <0x01>;
					#size-cells = <0x00>;
					num-cs = <0x02>;
					dmas = <0x31 0x37 0x31 0x36>;
					dma-names = "tx\0rx";
					status = "disabled";
					phandle = <0xb5>;
				};

				spi@50000 {
					reg = <0xc0 0x40050000 0x00 0x130>;
					compatible = "snps,dw-apb-ssi";
					interrupts = <0x13 0x04>;
					clocks = <0x30 0x0c>;
					clock-names = "ssi_clk";
					#address-cells = <0x01>;
					#size-cells = <0x00>;
					num-cs = <0x02>;
					dmas = <0x31 0x0d 0x31 0x0c>;
					dma-names = "tx\0rx";
					status = "disabled";
					pinctrl-names = "default";
					pinctrl-0 = <0x33 0x34>;
					cs-gpios = <0x35 0x08 0x01 0x35 0x07 0x01>;
					phandle = <0x6a>;

					spidev@0 {
						compatible = "spidev";
						reg = <0x00>;
						#address-cells = <0x01>;
						#size-cells = <0x00>;
						spi-max-frequency = <0x7735940>;
						phandle = <0xb6>;
					};

					spidev@1 {
						compatible = "spidev";
						reg = <0x01>;
						#address-cells = <0x01>;
						#size-cells = <0x00>;
						spi-max-frequency = <0x7735940>;
						phandle = <0xb7>;
					};
				};

				spi@54000 {
					reg = <0xc0 0x40054000 0x00 0x130>;
					compatible = "snps,dw-apb-ssi";
					interrupts = <0x14 0x04>;
					clocks = <0x30 0x0c>;
					clock-names = "ssi_clk";
					#address-cells = <0x01>;
					#size-cells = <0x00>;
					num-cs = <0x02>;
					dmas = <0x31 0x0f 0x31 0x0e>;
					dma-names = "tx\0rx";
					status = "disabled";
					phandle = <0xb8>;
				};

				spi@58000 {
					reg = <0xc0 0x40058000 0x00 0x130>;
					compatible = "snps,dw-apb-ssi";
					interrupts = <0x15 0x04>;
					clocks = <0x30 0x0c>;
					clock-names = "ssi_clk";
					#address-cells = <0x01>;
					#size-cells = <0x00>;
					num-cs = <0x02>;
					dmas = <0x31 0x11 0x31 0x10>;
					dma-names = "tx\0rx";
					status = "disabled";
					pinctrl-names = "default";
					pinctrl-0 = <0x36>;
					phandle = <0xb9>;
				};

				spi@5c000 {
					reg = <0xc0 0x4005c000 0x00 0x130>;
					compatible = "snps,dw-apb-ssi";
					interrupts = <0x16 0x04>;
					clocks = <0x30 0x0c>;
					clock-names = "ssi_clk";
					#address-cells = <0x01>;
					#size-cells = <0x00>;
					num-cs = <0x02>;
					dmas = <0x31 0x13 0x31 0x12>;
					dma-names = "tx\0rx";
					status = "disabled";
					pinctrl-names = "default";
					pinctrl-0 = <0x37>;
					phandle = <0xba>;
				};

				spi@60000 {
					reg = <0xc0 0x40060000 0x00 0x130>;
					compatible = "snps,dw-apb-ssi";
					interrupts = <0x17 0x04>;
					clocks = <0x30 0x0c>;
					clock-names = "ssi_clk";
					#address-cells = <0x00>;
					#size-cells = <0x00>;
					num-cs = <0x01>;
					spi-slave;
					dmas = <0x31 0x15 0x31 0x14>;
					dma-names = "tx\0rx";
					status = "disabled";
					pinctrl-names = "default";
					pinctrl-0 = <0x38>;
					phandle = <0xbb>;

					slave {
						compatible = "spidev";
						spi-max-frequency = <0xf4240>;
					};
				};

				spi@64000 {
					reg = <0xc0 0x40064000 0x00 0x130>;
					compatible = "snps,dw-apb-ssi";
					interrupts = <0x18 0x04>;
					clocks = <0x30 0x0c>;
					clock-names = "ssi_clk";
					#address-cells = <0x01>;
					#size-cells = <0x00>;
					num-cs = <0x02>;
					dmas = <0x31 0x17 0x31 0x16>;
					dma-names = "tx\0rx";
					status = "disabled";
					pinctrl-names = "default";
					pinctrl-0 = <0x39>;
					phandle = <0xbc>;
				};

				spi@68000 {
					reg = <0xc0 0x40068000 0x00 0x130>;
					compatible = "snps,dw-apb-ssi";
					interrupts = <0x36 0x04>;
					clocks = <0x30 0x0c>;
					clock-names = "ssi_clk";
					#address-cells = <0x01>;
					#size-cells = <0x00>;
					num-cs = <0x02>;
					dmas = <0x31 0x33 0x31 0x32>;
					dma-names = "tx\0rx";
					status = "disabled";
					phandle = <0xbd>;
				};

				spi@6c000 {
					reg = <0xc0 0x4006c000 0x00 0x130>;
					compatible = "snps,dw-apb-ssi";
					interrupts = <0x37 0x04>;
					clocks = <0x30 0x0c>;
					clock-names = "ssi_clk";
					#address-cells = <0x00>;
					#size-cells = <0x00>;
					num-cs = <0x01>;
					spi-slave;
					dmas = <0x31 0x35 0x31 0x34>;
					dma-names = "tx\0rx";
					status = "disabled";
					phandle = <0xbe>;

					slave {
						compatible = "spidev";
						spi-max-frequency = <0xf4240>;
					};
				};

				i2c@70000 {
					reg = <0xc0 0x40070000 0x00 0x1000>;
					compatible = "snps,designware-i2c";
					interrupts = <0x07 0x04>;
					clocks = <0x30 0x0c>;
					i2c-scl-rising-time-ns = <0x41>;
					i2c-scl-falling-time-ns = <0x64>;
					i2c-sda-hold-time-ns = <0x12c>;
					status = "disabled";
					pinctrl-0 = <0x3a>;
					pinctrl-names = "default";
					clock-frequency = <0x186a0>;
					phandle = <0x63>;
				};

				i2c@74000 {
					reg = <0xc0 0x40074000 0x00 0x1000>;
					compatible = "snps,designware-i2c";
					interrupts = <0x08 0x04>;
					clocks = <0x30 0x0c>;
					i2c-scl-rising-time-ns = <0x41>;
					i2c-scl-falling-time-ns = <0x64>;
					i2c-sda-hold-time-ns = <0x12c>;
					status = "disabled";
					pinctrl-names = "default";
					pinctrl-0 = <0x3b>;
					clock-frequency = <0x186a0>;
					phandle = <0x64>;
				};

				i2c@78000 {
					reg = <0xc0 0x40078000 0x00 0x1000>;
					compatible = "snps,designware-i2c";
					interrupts = <0x09 0x04>;
					clocks = <0x30 0x0c>;
					i2c-scl-rising-time-ns = <0x41>;
					i2c-scl-falling-time-ns = <0x64>;
					i2c-sda-hold-time-ns = <0x12c>;
					status = "disabled";
					pinctrl-names = "default";
					pinctrl-0 = <0x3c>;
					phandle = <0xbf>;
				};

				i2c@7c000 {
					reg = <0xc0 0x4007c000 0x00 0x1000>;
					compatible = "snps,designware-i2c";
					interrupts = <0x0a 0x04>;
					clocks = <0x30 0x0c>;
					i2c-scl-rising-time-ns = <0x41>;
					i2c-scl-falling-time-ns = <0x64>;
					i2c-sda-hold-time-ns = <0x12c>;
					status = "disabled";
					pinctrl-names = "default";
					pinctrl-0 = <0x3d>;
					phandle = <0xc0>;
				};

				i2c@80000 {
					reg = <0xc0 0x40080000 0x00 0x1000>;
					compatible = "snps,designware-i2c";
					interrupts = <0x0b 0x04>;
					clocks = <0x30 0x0c>;
					i2c-scl-rising-time-ns = <0x41>;
					i2c-scl-falling-time-ns = <0x64>;
					i2c-sda-hold-time-ns = <0x12c>;
					status = "disabled";
					pinctrl-0 = <0x3e>;
					pinctrl-names = "default";
					clock-frequency = <0x186a0>;
					phandle = <0x65>;
				};

				i2c@84000 {
					reg = <0xc0 0x40084000 0x00 0x1000>;
					compatible = "snps,designware-i2c";
					interrupts = <0x0c 0x04>;
					clocks = <0x30 0x0c>;
					i2c-scl-rising-time-ns = <0x41>;
					i2c-scl-falling-time-ns = <0x64>;
					i2c-sda-hold-time-ns = <0x12c>;
					status = "disabled";
					phandle = <0xc1>;
				};

				i2c@88000 {
					reg = <0xc0 0x40088000 0x00 0x1000>;
					compatible = "snps,designware-i2c";
					interrupts = <0x0d 0x04>;
					clocks = <0x30 0x0c>;
					i2c-scl-rising-time-ns = <0x41>;
					i2c-scl-falling-time-ns = <0x64>;
					i2c-sda-hold-time-ns = <0x12c>;
					status = "disabled";
					pinctrl-0 = <0x3f>;
					pinctrl-names = "default";
					clock-frequency = <0x186a0>;
					phandle = <0x66>;
				};

				pwm@98000 {
					compatible = "raspberrypi,rp1-pwm";
					reg = <0xc0 0x40098000 0x00 0x100>;
					#pwm-cells = <0x03>;
					clocks = <0x30 0x11>;
					assigned-clocks = <0x30 0x11>;
					assigned-clock-rates = <0x5dc000>;
					status = "disabled";
					phandle = <0xc2>;
				};

				pwm@9c000 {
					compatible = "raspberrypi,rp1-pwm";
					reg = <0xc0 0x4009c000 0x00 0x100>;
					#pwm-cells = <0x03>;
					clocks = <0x30 0x12>;
					assigned-clocks = <0x30 0x12>;
					assigned-clock-rates = <0x5dc000>;
					status = "disabled";
					pinctrl-0 = <0x40>;
					pinctrl-names = "default";
					phandle = <0x60>;
				};

				i2s@a0000 {
					reg = <0xc0 0x400a0000 0x00 0x1000>;
					compatible = "snps,designware-i2s";
					clocks = <0x30 0x15>;
					clock-names = "i2sclk";
					#sound-dai-cells = <0x00>;
					dmas = <0x31 0x20 0x31 0x1f>;
					dma-names = "tx\0rx";
					status = "disabled";
					pinctrl-names = "default";
					pinctrl-0 = <0x41>;
					phandle = <0xc3>;
				};

				i2s@a4000 {
					reg = <0xc0 0x400a4000 0x00 0x1000>;
					compatible = "snps,designware-i2s";
					clocks = <0x30 0x15>;
					clock-names = "i2sclk";
					#sound-dai-cells = <0x00>;
					dmas = <0x31 0x22 0x31 0x21>;
					dma-names = "tx\0rx";
					status = "disabled";
					pinctrl-names = "default";
					pinctrl-0 = <0x42>;
					phandle = <0xc4>;
				};

				i2s@a8000 {
					reg = <0xc0 0x400a8000 0x00 0x1000>;
					compatible = "snps,designware-i2s";
					clocks = <0x30 0x15>;
					status = "disabled";
					phandle = <0xc5>;
				};

				sdio_clk0@b0004 {
					compatible = "raspberrypi,rp1-sdio-clk";
					reg = <0xc0 0x400b0004 0x00 0x1c>;
					clocks = <0x43 0x44>;
					clock-names = "src\0base";
					#clock-cells = <0x00>;
					status = "disabled";
					phandle = <0x4a>;
				};

				sdio_clk1@b4004 {
					compatible = "raspberrypi,rp1-sdio-clk";
					reg = <0xc0 0x400b4004 0x00 0x1c>;
					clocks = <0x43 0x44>;
					clock-names = "src\0base";
					#clock-cells = <0x00>;
					status = "disabled";
					phandle = <0x4b>;
				};

				adc@c8000 {
					compatible = "raspberrypi,rp1-adc";
					reg = <0xc0 0x400c8000 0x00 0x4000>;
					clocks = <0x30 0x1e>;
					clock-names = "adcclk";
					#clock-cells = <0x00>;
					vref-supply = <0x45>;
					status = "okay";
					phandle = <0xc6>;
				};

				gpio@d0000 {
					reg = <0xc0 0x400d0000 0x00 0xc000 0xc0 0x400e0000 0x00 0xc000 0xc0 0x400f0000 0x00 0xc000>;
					compatible = "raspberrypi,rp1-gpio";
					interrupts = <0x00 0x04 0x01 0x04 0x02 0x04>;
					gpio-controller;
					#gpio-cells = <0x02>;
					interrupt-controller;
					#interrupt-cells = <0x02>;
					status = "okay";
					gpio-line-names = "ID_SDA\0ID_SCL\0GPIO2\0GPIO3\0GPIO4\0GPIO5\0GPIO6\0GPIO7\0GPIO8\0GPIO9\0GPIO10\0GPIO11\0GPIO12\0GPIO13\0GPIO14\0GPIO15\0GPIO16\0GPIO17\0GPIO18\0GPIO19\0GPIO20\0GPIO21\0GPIO22\0GPIO23\0GPIO24\0GPIO25\0GPIO26\0GPIO27\0PCIE_RP1_WAKE\0FAN_TACH\0HOST_SDA\0HOST_SCL\0ETH_RST_N\0-\0CD0_IO0_MICCLK\0CD0_IO0_MICDAT0\0RP1_PCIE_CLKREQ_N\0-\0CD0_SDA\0CD0_SCL\0CD1_SDA\0CD1_SCL\0USB_VBUS_EN\0USB_OC_N\0RP1_STAT_LED\0FAN_PWM\0CD1_IO0_MICCLK\02712_WAKE\0CD1_IO1_MICDAT1\0EN_MAX_USB_CUR\0-\0-\0-\0-";
					phandle = <0x35>;

					rp1_uart0_14_15 {
						phandle = <0x32>;

						pin_txd {
							function = "uart0";
							pins = "gpio14";
							bias-disable;
						};

						pin_rxd {
							function = "uart0";
							pins = "gpio15";
							bias-pull-up;
						};
					};

					rp1_uart0_ctsrts_16_17 {
						phandle = <0xc7>;

						pin_cts {
							function = "uart0";
							pins = "gpio16";
							bias-pull-up;
						};

						pin_rts {
							function = "uart0";
							pins = "gpio17";
							bias-disable;
						};
					};

					rp1_uart1_0_1 {
						phandle = <0xc8>;

						pin_txd {
							function = "uart1";
							pins = "gpio0";
							bias-disable;
						};

						pin_rxd {
							function = "uart1";
							pins = "gpio1";
							bias-pull-up;
						};
					};

					rp1_uart1_ctsrts_2_3 {
						phandle = <0xc9>;

						pin_cts {
							function = "uart1";
							pins = "gpio2";
							bias-pull-up;
						};

						pin_rts {
							function = "uart1";
							pins = "gpio3";
							bias-disable;
						};
					};

					rp1_uart2_4_5 {
						phandle = <0xca>;

						pin_txd {
							function = "uart2";
							pins = "gpio4";
							bias-disable;
						};

						pin_rxd {
							function = "uart2";
							pins = "gpio5";
							bias-pull-up;
						};
					};

					rp1_uart2_ctsrts_6_7 {
						phandle = <0xcb>;

						pin_cts {
							function = "uart2";
							pins = "gpio6";
							bias-pull-up;
						};

						pin_rts {
							function = "uart2";
							pins = "gpio7";
							bias-disable;
						};
					};

					rp1_uart3_8_9 {
						phandle = <0xcc>;

						pin_txd {
							function = "uart3";
							pins = "gpio8";
							bias-disable;
						};

						pin_rxd {
							function = "uart3";
							pins = "gpio9";
							bias-pull-up;
						};
					};

					rp1_uart3_ctsrts_10_11 {
						phandle = <0xcd>;

						pin_cts {
							function = "uart3";
							pins = "gpio10";
							bias-pull-up;
						};

						pin_rts {
							function = "uart3";
							pins = "gpio11";
							bias-disable;
						};
					};

					rp1_uart4_12_13 {
						phandle = <0xce>;

						pin_txd {
							function = "uart4";
							pins = "gpio12";
							bias-disable;
						};

						pin_rxd {
							function = "uart4";
							pins = "gpio13";
							bias-pull-up;
						};
					};

					rp1_uart4_ctsrts_14_15 {
						phandle = <0xcf>;

						pin_cts {
							function = "uart4";
							pins = "gpio14";
							bias-pull-up;
						};

						pin_rts {
							function = "uart4";
							pins = "gpio15";
							bias-disable;
						};
					};

					rp1_sdio0_22_27 {
						phandle = <0xd0>;

						pin_clk {
							function = "sd0";
							pins = "gpio22";
							bias-disable;
							drive-strength = <0x0c>;
							slew-rate = <0x01>;
						};

						pin_cmd {
							function = "sd0";
							pins = "gpio23";
							bias-pull-up;
							drive-strength = <0x0c>;
							slew-rate = <0x01>;
						};

						pins_dat {
							function = "sd0";
							pins = "gpio24\0gpio25\0gpio26\0gpio27";
							bias-pull-up;
							drive-strength = <0x0c>;
							slew-rate = <0x01>;
						};
					};

					rp1_sdio1_28_33 {
						phandle = <0xd1>;

						pin_clk {
							function = "sd1";
							pins = "gpio28";
							bias-disable;
							drive-strength = <0x0c>;
							slew-rate = <0x01>;
						};

						pin_cmd {
							function = "sd1";
							pins = "gpio29";
							bias-pull-up;
							drive-strength = <0x0c>;
							slew-rate = <0x01>;
						};

						pins_dat {
							function = "sd1";
							pins = "gpio30\0gpio31\0gpio32\0gpio33";
							bias-pull-up;
							drive-strength = <0x0c>;
							slew-rate = <0x01>;
						};
					};

					rp1_i2s0_18_21 {
						function = "i2s0";
						pins = "gpio18\0gpio19\0gpio20\0gpio21";
						bias-disable;
						phandle = <0x41>;
					};

					rp1_i2s1_18_21 {
						function = "i2s1";
						pins = "gpio18\0gpio19\0gpio20\0gpio21";
						bias-disable;
						phandle = <0x42>;
					};

					rp1_i2c4_34_35 {
						function = "i2c4";
						pins = "gpio34\0gpio35";
						drive-strength = <0x0c>;
						bias-pull-up;
						phandle = <0xd2>;
					};

					rp1_i2c6_38_39 {
						function = "i2c6";
						pins = "gpio38\0gpio39";
						drive-strength = <0x0c>;
						bias-pull-up;
						phandle = <0x3f>;
					};

					rp1_i2c4_40_41 {
						function = "i2c4";
						pins = "gpio40\0gpio41";
						drive-strength = <0x0c>;
						bias-pull-up;
						phandle = <0x3e>;
					};

					rp1_i2c5_44_45 {
						function = "i2c5";
						pins = "gpio44\0gpio45";
						drive-strength = <0x0c>;
						bias-pull-up;
						phandle = <0xd3>;
					};

					rp1_i2c0_0_1 {
						function = "i2c0";
						pins = "gpio0\0gpio1";
						drive-strength = <0x0c>;
						bias-pull-up;
						phandle = <0x3a>;
					};

					rp1_i2c0_8_9 {
						function = "i2c0";
						pins = "gpio8\0gpio9";
						drive-strength = <0x0c>;
						bias-pull-up;
						phandle = <0xd4>;
					};

					rp1_i2c1_2_3 {
						function = "i2c1";
						pins = "gpio2\0gpio3";
						drive-strength = <0x0c>;
						bias-pull-up;
						phandle = <0x3b>;
					};

					rp1_i2c1_10_11 {
						function = "i2c1";
						pins = "gpio10\0gpio11";
						drive-strength = <0x0c>;
						bias-pull-up;
						phandle = <0xd5>;
					};

					rp1_i2c2_4_5 {
						function = "i2c2";
						pins = "gpio4\0gpio5";
						drive-strength = <0x0c>;
						bias-pull-up;
						phandle = <0x3c>;
					};

					rp1_i2c2_12_13 {
						function = "i2c2";
						pins = "gpio12\0gpio13";
						drive-strength = <0x0c>;
						bias-pull-up;
						phandle = <0xd6>;
					};

					rp1_i2c3_6_7 {
						function = "i2c3";
						pins = "gpio6\0gpio7";
						drive-strength = <0x0c>;
						bias-pull-up;
						phandle = <0x3d>;
					};

					rp1_i2c3_14_15 {
						function = "i2c3";
						pins = "gpio14\0gpio15";
						drive-strength = <0x0c>;
						bias-pull-up;
						phandle = <0xd7>;
					};

					rp1_i2c3_22_23 {
						function = "i2c3";
						pins = "gpio22\0gpio23";
						drive-strength = <0x0c>;
						bias-pull-up;
						phandle = <0xd8>;
					};

					rp1_dpi_16bit_gpio2 {
						function = "dpi";
						pins = "gpio2\0gpio3\0gpio4\0gpio5\0gpio6\0gpio7\0gpio8\0gpio9\0gpio10\0gpio11\0gpio12\0gpio13\0gpio14\0gpio15\0gpio16\0gpio17\0gpio18\0gpio19";
						bias-disable;
						phandle = <0xd9>;
					};

					rp1_dpi_16bit_cpadhi_gpio2 {
						function = "dpi";
						pins = "gpio2\0gpio3\0gpio4\0gpio5\0gpio6\0gpio7\0gpio8\0gpio12\0gpio13\0gpio14\0gpio15\0gpio16\0gpio17\0gpio20\0gpio21\0gpio22\0gpio23\0gpio24";
						bias-disable;
						phandle = <0xda>;
					};

					rp1_dpi_16bit_pad666_gpio2 {
						function = "dpi";
						pins = "gpio2\0gpio3\0gpio5\0gpio6\0gpio7\0gpio8\0gpio9\0gpio12\0gpio13\0gpio14\0gpio15\0gpio16\0gpio17\0gpio21\0gpio22\0gpio23\0gpio24\0gpio25";
						bias-disable;
						phandle = <0xdb>;
					};

					rp1_dpi_18bit_gpio2 {
						function = "dpi";
						pins = "gpio2\0gpio3\0gpio4\0gpio5\0gpio6\0gpio7\0gpio8\0gpio9\0gpio10\0gpio11\0gpio12\0gpio13\0gpio14\0gpio15\0gpio16\0gpio17\0gpio18\0gpio19\0gpio20\0gpio21";
						bias-disable;
						phandle = <0xdc>;
					};

					rp1_dpi_18bit_cpadhi_gpio2 {
						function = "dpi";
						pins = "gpio2\0gpio3\0gpio4\0gpio5\0gpio6\0gpio7\0gpio8\0gpio9\0gpio12\0gpio13\0gpio14\0gpio15\0gpio16\0gpio17\0gpio20\0gpio21\0gpio22\0gpio23\0gpio24\0gpio25";
						bias-disable;
						phandle = <0xdd>;
					};

					rp1_dpi_24bit_gpio2 {
						function = "dpi";
						pins = "gpio2\0gpio3\0gpio4\0gpio5\0gpio6\0gpio7\0gpio8\0gpio9\0gpio10\0gpio11\0gpio12\0gpio13\0gpio14\0gpio15\0gpio16\0gpio17\0gpio18\0gpio19\0gpio20\0gpio21\0gpio22\0gpio23\0gpio24\0gpio25\0gpio26\0gpio27";
						bias-disable;
						phandle = <0xde>;
					};

					rp1_dpi_hvsync {
						function = "dpi";
						pins = "gpio2\0gpio3";
						bias-disable;
						phandle = <0xdf>;
					};

					rp1_dpi_16bit_gpio0 {
						function = "dpi";
						pins = "gpio0\0gpio1\0gpio2\0gpio3\0gpio4\0gpio5\0gpio6\0gpio7\0gpio8\0gpio9\0gpio10\0gpio11\0gpio12\0gpio13\0gpio14\0gpio15\0gpio16\0gpio17\0gpio18\0gpio19";
						bias-disable;
						phandle = <0xe0>;
					};

					rp1_dpi_16bit_cpadhi_gpio0 {
						function = "dpi";
						pins = "gpio0\0gpio1\0gpio2\0gpio3\0gpio4\0gpio5\0gpio6\0gpio7\0gpio8\0gpio12\0gpio13\0gpio14\0gpio15\0gpio16\0gpio17\0gpio20\0gpio21\0gpio22\0gpio23\0gpio24";
						bias-disable;
						phandle = <0xe1>;
					};

					rp1_dpi_16bit_pad666_gpio0 {
						function = "dpi";
						pins = "gpio0\0gpio1\0gpio2\0gpio3\0gpio5\0gpio6\0gpio7\0gpio8\0gpio9\0gpio12\0gpio13\0gpio14\0gpio15\0gpio16\0gpio17\0gpio21\0gpio22\0gpio23\0gpio24\0gpio25";
						bias-disable;
						phandle = <0xe2>;
					};

					rp1_dpi_18bit_gpio0 {
						function = "dpi";
						pins = "gpio0\0gpio1\0gpio2\0gpio3\0gpio4\0gpio5\0gpio6\0gpio7\0gpio8\0gpio9\0gpio10\0gpio11\0gpio12\0gpio13\0gpio14\0gpio15\0gpio16\0gpio17\0gpio18\0gpio19\0gpio20\0gpio21";
						bias-disable;
						phandle = <0xe3>;
					};

					rp1_dpi_18bit_cpadhi_gpio0 {
						function = "dpi";
						pins = "gpio0\0gpio1\0gpio2\0gpio3\0gpio4\0gpio5\0gpio6\0gpio7\0gpio8\0gpio9\0gpio12\0gpio13\0gpio14\0gpio15\0gpio16\0gpio17\0gpio20\0gpio21\0gpio22\0gpio23\0gpio24\0gpio25";
						bias-disable;
						phandle = <0xe4>;
					};

					rp1_dpi_24bit_gpio0 {
						function = "dpi";
						pins = "gpio0\0gpio1\0gpio2\0gpio3\0gpio4\0gpio5\0gpio6\0gpio7\0gpio8\0gpio9\0gpio10\0gpio11\0gpio12\0gpio13\0gpio14\0gpio15\0gpio16\0gpio17\0gpio18\0gpio19\0gpio20\0gpio21\0gpio22\0gpio23\0gpio24\0gpio25\0gpio26\0gpio27";
						bias-disable;
						phandle = <0xe5>;
					};

					rp1_gpclksrc0_gpio4 {
						function = "gpclk0";
						pins = "gpio4";
						bias-disable;
						phandle = <0xe6>;
					};

					rp1_gpclksrc0_gpio20 {
						function = "gpclk0";
						pins = "gpio20";
						bias-disable;
						phandle = <0xe7>;
					};

					rp1_gpclksrc1_gpio5 {
						function = "gpclk1";
						pins = "gpio5";
						bias-disable;
						phandle = <0xe8>;
					};

					rp1_gpclksrc1_gpio18 {
						function = "gpclk1";
						pins = "gpio18";
						bias-disable;
						phandle = <0xe9>;
					};

					rp1_gpclksrc1_gpio21 {
						function = "gpclk1";
						pins = "gpio21";
						bias-disable;
						phandle = <0xea>;
					};

					rp1_pwm1_gpio45 {
						function = "pwm1";
						pins = "gpio45";
						bias-pull-down;
						phandle = <0x40>;
					};

					rp1_spi0_gpio9 {
						function = "spi0";
						pins = "gpio9\0gpio10\0gpio11";
						bias-disable;
						drive-strength = <0x0c>;
						slew-rate = <0x01>;
						phandle = <0x33>;
					};

					rp1_spi0_cs_gpio7 {
						function = "spi0";
						pins = "gpio7\0gpio8";
						bias-pull-up;
						phandle = <0x34>;
					};

					rp1_spi1_gpio19 {
						function = "spi1";
						pins = "gpio19\0gpio20\0gpio21";
						bias-disable;
						drive-strength = <0x0c>;
						slew-rate = <0x01>;
						phandle = <0xeb>;
					};

					rp1_spi2_gpio1 {
						function = "spi2";
						pins = "gpio1\0gpio2\0gpio3";
						bias-disable;
						drive-strength = <0x0c>;
						slew-rate = <0x01>;
						phandle = <0x36>;
					};

					rp1_spi3_gpio5 {
						function = "spi3";
						pins = "gpio5\0gpio6\0gpio7";
						bias-disable;
						drive-strength = <0x0c>;
						slew-rate = <0x01>;
						phandle = <0x37>;
					};

					rp1_spi4_gpio9 {
						function = "spi4";
						pins = "gpio9\0gpio10\0gpio11";
						bias-disable;
						drive-strength = <0x0c>;
						slew-rate = <0x01>;
						phandle = <0x38>;
					};

					rp1_spi5_gpio13 {
						function = "spi5";
						pins = "gpio13\0gpio14\0gpio15";
						bias-disable;
						drive-strength = <0x0c>;
						slew-rate = <0x01>;
						phandle = <0x39>;
					};

					rp1_spi8_gpio49 {
						function = "spi8";
						pins = "gpio49\0gpio50\0gpio51";
						bias-disable;
						drive-strength = <0x0c>;
						slew-rate = <0x01>;
						phandle = <0xec>;
					};

					rp1_spi8_cs_gpio52 {
						function = "spi0";
						pins = "gpio52\0gpio53";
						bias-pull-up;
						phandle = <0xed>;
					};

					usb_vbus_pins {
						function = "vbus1";
						pins = "gpio42\0gpio43";
						phandle = <0x4c>;
					};
				};

				ethernet@100000 {
					reg = <0xc0 0x40100000 0x00 0x6000>;
					compatible = "cdns,macb";
					#address-cells = <0x01>;
					#size-cells = <0x00>;
					interrupts = <0x06 0x04>;
					clocks = <0x46 0x47 0x30 0x1d>;
					clock-names = "pclk\0hclk\0tsu_clk";
					phy-mode = "rgmii-id";
					cdns,aw2w-max-pipe = [08];
					cdns,ar2r-max-pipe = [08];
					cdns,use-aw2b-fill;
					local-mac-address = [00 00 00 00 00 00];
					status = "okay";
					phy-handle = <0x48>;
					phy-reset-gpios = <0x35 0x20 0x01>;
					phy-reset-duration = <0x05>;
					phandle = <0xee>;

					ethernet-phy@1 {
						reg = <0x01>;
						brcm,powerdown-enable;
						phandle = <0x48>;
					};
				};

				csi@110000 {
					compatible = "raspberrypi,rp1-cfe";
					reg = <0xc0 0x40110000 0x00 0x100 0xc0 0x40114000 0x00 0x100 0xc0 0x40120000 0x00 0x100 0xc0 0x40124000 0x00 0x1000>;
					interrupts = <0x2f 0x04>;
					clocks = <0x30 0x16>;
					assigned-clocks = <0x30 0x16>;
					assigned-clock-rates = <0x17d7840>;
					#address-cells = <0x01>;
					#size-cells = <0x00>;
					status = "disabled";
					iommus = <0x49>;
					phandle = <0xef>;
				};

				csi@128000 {
					compatible = "raspberrypi,rp1-cfe";
					reg = <0xc0 0x40128000 0x00 0x100 0xc0 0x4012c000 0x00 0x100 0xc0 0x40138000 0x00 0x100 0xc0 0x4013c000 0x00 0x1000>;
					interrupts = <0x30 0x04>;
					clocks = <0x30 0x17>;
					assigned-clocks = <0x30 0x17>;
					assigned-clock-rates = <0x17d7840>;
					#address-cells = <0x01>;
					#size-cells = <0x00>;
					status = "disabled";
					iommus = <0x49>;
					phandle = <0xf0>;
				};

				mmc@180000 {
					reg = <0xc0 0x40180000 0x00 0x100>;
					compatible = "raspberrypi,rp1-dwcmshc";
					interrupts = <0x11 0x04>;
					clocks = <0x30 0x0c 0x44 0x30 0x1f 0x4a>;
					clock-names = "bus\0core\0timeout\0sdio";
					no-1-8-v;
					bus-width = <0x04>;
					vmmc-supply = <0x45>;
					broken-cd;
					status = "disabled";
					phandle = <0xf1>;
				};

				mmc@184000 {
					reg = <0xc0 0x40184000 0x00 0x100>;
					compatible = "raspberrypi,rp1-dwcmshc";
					interrupts = <0x12 0x04>;
					clocks = <0x30 0x0c 0x44 0x30 0x1f 0x4b>;
					clock-names = "bus\0core\0timeout\0sdio";
					bus-width = <0x04>;
					vmmc-supply = <0x45>;
					sdhci-caps-mask = <0x03 0x00>;
					broken-cd;
					status = "disabled";
					phandle = <0xf2>;
				};

				dma@188000 {
					reg = <0xc0 0x40188000 0x00 0x1000>;
					compatible = "snps,axi-dma-1.01a";
					interrupts = <0x28 0x04>;
					clocks = <0x44 0x30 0x0c>;
					clock-names = "core-clk\0cfgr-clk";
					#dma-cells = <0x01>;
					dma-channels = <0x08>;
					snps,dma-masters = <0x01>;
					snps,dma-targets = <0x40>;
					snps,data-width = <0x04>;
					snps,block-size = <0x40000 0x40000 0x40000 0x40000 0x40000 0x40000 0x40000 0x40000>;
					snps,priority = <0x00 0x01 0x02 0x03 0x04 0x05 0x06 0x07>;
					snps,axi-max-burst-len = <0x08>;
					status = "okay";
					phandle = <0x31>;
				};

				usb@200000 {
					reg = <0xc0 0x40200000 0x00 0x100000>;
					compatible = "snps,dwc3";
					dr_mode = "host";
					usb3-lpm-capable;
					snps,axi-pipe-limit = [08];
					snps,dis_rxdet_inp3_quirk;
					snps,parkmode-disable-ss-quirk;
					snps,parkmode-disable-hs-quirk;
					snps,parkmode-disable-fsls-quirk;
					snps,tx-max-burst-prd = <0x08>;
					snps,tx-thr-num-pkt-prd = <0x02>;
					interrupts = <0x1f 0x01>;
					status = "okay";
					pinctrl-0 = <0x4c>;
					pinctrl-names = "default";
					phandle = <0xf3>;
				};

				usb@300000 {
					reg = <0xc0 0x40300000 0x00 0x100000>;
					compatible = "snps,dwc3";
					dr_mode = "host";
					usb3-lpm-capable;
					snps,axi-pipe-limit = [08];
					snps,dis_rxdet_inp3_quirk;
					snps,parkmode-disable-ss-quirk;
					snps,parkmode-disable-hs-quirk;
					snps,parkmode-disable-fsls-quirk;
					snps,tx-max-burst-prd = <0x08>;
					snps,tx-thr-num-pkt-prd = <0x02>;
					interrupts = <0x24 0x01>;
					status = "okay";
					phandle = <0xf4>;
				};

				dsi@110000 {
					compatible = "raspberrypi,rp1dsi";
					status = "disabled";
					reg = <0xc0 0x40118000 0x00 0x1000 0xc0 0x4011c000 0x00 0x1000 0xc0 0x40120000 0x00 0x1000>;
					interrupts = <0x2f 0x04>;
					clocks = <0x30 0x16 0x30 0x29 0x4d 0x2f>;
					clock-names = "cfgclk\0dpiclk\0byteclk\0refclk";
					assigned-clocks = <0x30 0x16 0x30 0x29>;
					assigned-clock-rates = <0x17d7840>;
					assigned-clock-parents = <0x00 0x4d>;
					iommus = <0x49>;
					phandle = <0xf5>;
				};

				dsi@128000 {
					compatible = "raspberrypi,rp1dsi";
					status = "disabled";
					reg = <0xc0 0x40130000 0x00 0x1000 0xc0 0x40134000 0x00 0x1000 0xc0 0x40138000 0x00 0x1000>;
					interrupts = <0x30 0x04>;
					clocks = <0x30 0x17 0x30 0x2a 0x4e 0x2f>;
					clock-names = "cfgclk\0dpiclk\0byteclk\0refclk";
					assigned-clocks = <0x30 0x17 0x30 0x2a>;
					assigned-clock-rates = <0x17d7840>;
					assigned-clock-parents = <0x00 0x4e>;
					iommus = <0x49>;
					phandle = <0xf6>;
				};

				vec@144000 {
					compatible = "raspberrypi,rp1vec";
					status = "disabled";
					reg = <0xc0 0x40144000 0x00 0x1000 0xc0 0x40140000 0x00 0x1000>;
					interrupts = <0x31 0x04>;
					clocks = <0x30 0x27>;
					assigned-clocks = <0x30 0x02 0x30 0x0b 0x30 0x27>;
					assigned-clock-rates = <0x46cf7100 0x66ff300 0x66ff300>;
					assigned-clock-parents = <0x00 0x30 0x02 0x30 0x0b>;
					iommus = <0x49>;
					phandle = <0xf7>;
				};

				dpi@148000 {
					compatible = "raspberrypi,rp1dpi";
					status = "disabled";
					reg = <0xc0 0x40148000 0x00 0x1000 0xc0 0x40140000 0x00 0x1000>;
					interrupts = <0x31 0x04>;
					clocks = <0x30 0x28 0x30 0x05 0x30 0x02>;
					clock-names = "dpiclk\0plldiv\0pllcore";
					assigned-clocks = <0x30 0x28>;
					assigned-clock-parents = <0x30 0x05>;
					iommus = <0x49>;
					phandle = <0xf8>;
				};

				gpiomem@d0000 {
					compatible = "raspberrypi,gpiomem";
					reg = <0xc0 0x400d0000 0x00 0x30000>;
					chardev-name = "gpiomem0";
				};
			};
		};

		msi-controller@130000 {
			compatible = "brcm,bcm2712-mip-intc";
			reg = <0x10 0x130000 0x00 0xc0>;
			msi-controller;
			interrupt-controller;
			#interrupt-cells = <0x02>;
			brcm,msi-base-spi = <0x80>;
			brcm,msi-num-spis = <0x40>;
			brcm,msi-offset = <0x00>;
			brcm,msi-pci-addr = <0xff 0xfffff000>;
			phandle = <0x2d>;
		};

		msi-controller@131000 {
			compatible = "brcm,bcm2712-mip-intc";
			reg = <0x10 0x131000 0x00 0xc0>;
			msi-controller;
			interrupt-controller;
			#interrupt-cells = <0x02>;
			brcm,msi-base-spi = <0xf7>;
			brcm,msi-num-spis = <0x08>;
			brcm,msi-offset = <0x08>;
			brcm,msi-pci-addr = <0xff 0xffffe000>;
			phandle = <0x2c>;
		};

		syscon@400018 {
			compatible = "brcm,syscon-piarbctl\0syscon\0simple-mfd";
			reg = <0x10 0x400018 0x00 0x18>;
			phandle = <0xf9>;
		};

		usb@480000 {
			compatible = "brcm,bcm2835-usb";
			reg = <0x10 0x480000 0x00 0x10000>;
			interrupts = <0x00 0x49 0x04>;
			#address-cells = <0x01>;
			#size-cells = <0x00>;
			clocks = <0x4f>;
			clock-names = "otg";
			phys = <0x50>;
			phy-names = "usb2-phy";
			status = "disabled";
			power-domains = <0x51 0x06>;
			phandle = <0xfa>;
		};

		codec@800000 {
			compatible = "raspberrypi,rpivid-vid-decoder";
			reg = <0x10 0x800000 0x00 0x10000 0x10 0x840000 0x00 0x1000>;
			reg-names = "hevc\0intc";
			interrupts = <0x00 0x62 0x04>;
			clocks = <0x0a 0x0b>;
			clock-names = "hevc";
			iommus = <0x52>;
			status = "okay";
			phandle = <0xfb>;
		};

		mmc@fff000 {
			compatible = "brcm,bcm2712-sdhci";
			reg = <0x10 0xfff000 0x00 0x260 0x10 0xfff400 0x00 0x200 0x10 0x15040b0 0x00 0x04 0x10 0x15200f0 0x00 0x24>;
			reg-names = "host\0cfg\0busisol\0lcpll";
			interrupts = <0x00 0x111 0x04>;
			clocks = <0x53>;
			sdhci-caps-mask = <0xc000 0x00>;
			sdhci-caps = <0x00 0x00>;
			supports-cqe;
			mmc-ddr-3_3v;
			pinctrl-0 = <0x54 0x55>;
			pinctrl-names = "default";
			vqmmc-supply = <0x56>;
			vmmc-supply = <0x57>;
			bus-width = <0x04>;
			sd-uhs-sdr50;
			sd-uhs-ddr50;
			sd-uhs-sdr104;
			cd-gpios = <0x58 0x05 0x01>;
			status = "okay";
			phandle = <0xfc>;
		};

		mmc@1100000 {
			compatible = "brcm,bcm2712-sdhci";
			reg = <0x10 0x1100000 0x00 0x260 0x10 0x1100400 0x00 0x200>;
			reg-names = "host\0cfg";
			interrupts = <0x00 0x112 0x04>;
			clocks = <0x53>;
			sdhci-caps-mask = <0xc000 0x00>;
			sdhci-caps = <0x00 0x00>;
			supports-cqe;
			mmc-ddr-3_3v;
			status = "okay";
			pinctrl-0 = <0x59>;
			pinctrl-names = "default";
			bus-width = <0x04>;
			vmmc-supply = <0x5a>;
			sd-uhs-ddr50;
			non-removable;
			#address-cells = <0x01>;
			#size-cells = <0x00>;
			phandle = <0xfd>;

			wifi@1 {
				reg = <0x01>;
				compatible = "brcm,bcm4329-fmac";
				local-mac-address = [00 00 00 00 00 00];
				phandle = <0x6b>;
			};
		};

		reset-controller@1504318 {
			compatible = "brcm,brcmstb-reset";
			reg = <0x10 0x1504318 0x00 0x30>;
			#reset-cells = <0x01>;
			phandle = <0x29>;
		};

		v3d@2000000 {
			compatible = "brcm,2712-v3d";
			reg = <0x10 0x2000000 0x00 0x4000 0x10 0x2008000 0x00 0x6000>;
			reg-names = "hub\0core0";
			power-domains = <0x5b 0x01>;
			resets = <0x5b 0x00>;
			clocks = <0x0a 0x05>;
			clocks-names = "v3d";
			interrupts = <0x00 0xfa 0x04 0x00 0xf9 0x04>;
			status = "disabled";
			phandle = <0xfe>;
		};

		interrupt-controller@7fff9000 {
			interrupt-controller;
			#interrupt-cells = <0x03>;
			compatible = "arm,gic-400";
			reg = <0x10 0x7fff9000 0x00 0x1000 0x10 0x7fffa000 0x00 0x2000 0x10 0x7fffc000 0x00 0x2000 0x10 0x7fffe000 0x00 0x2000>;
			interrupts = <0x01 0x09 0xf04>;
			phandle = <0x01>;
		};

		pisp_be@880000 {
			compatible = "raspberrypi,pispbe";
			reg = <0x10 0x880000 0x00 0x4000>;
			interrupts = <0x00 0x48 0x04>;
			clocks = <0x0a 0x07>;
			clocks-names = "isp_be";
			status = "okay";
			iommus = <0x52>;
			phandle = <0xff>;
		};
	};

	clocks {
		phandle = <0x100>;

		clk-osc {
			compatible = "fixed-clock";
			#clock-cells = <0x00>;
			clock-output-names = "osc";
			clock-frequency = <0x337f980>;
			phandle = <0x15>;
		};

		clk-usb {
			compatible = "fixed-clock";
			#clock-cells = <0x00>;
			clock-output-names = "otg";
			clock-frequency = <0x1c9c3800>;
			phandle = <0x4f>;
		};

		clk_vpu {
			#clock-cells = <0x00>;
			compatible = "fixed-clock";
			clock-frequency = <0x2cb41780>;
			clock-output-names = "vpu-clock";
			phandle = <0x0f>;
		};

		clk_uart {
			#clock-cells = <0x00>;
			compatible = "fixed-clock";
			clock-frequency = <0x8ca000>;
			clock-output-names = "uart-clock";
			phandle = <0x0e>;
		};

		clk_emmc2 {
			#clock-cells = <0x00>;
			compatible = "fixed-clock";
			clock-frequency = <0x337f980>;
			clock-output-names = "emmc2-clock";
			phandle = <0x53>;
		};

		clk_xosc {
			compatible = "fixed-clock";
			#clock-cells = <0x00>;
			clock-output-names = "xosc";
			clock-frequency = <0x2faf080>;
			phandle = <0x2f>;
		};

		macb_pclk {
			compatible = "fixed-clock";
			#clock-cells = <0x00>;
			clock-output-names = "pclk";
			clock-frequency = <0xbebc200>;
			phandle = <0x46>;
		};

		macb_hclk {
			compatible = "fixed-clock";
			#clock-cells = <0x00>;
			clock-output-names = "hclk";
			clock-frequency = <0xbebc200>;
			phandle = <0x47>;
		};

		sdio_src {
			compatible = "fixed-clock";
			#clock-cells = <0x00>;
			clock-output-names = "src";
			clock-frequency = <0x3b9aca00>;
			phandle = <0x43>;
		};

		sdhci_core {
			compatible = "fixed-clock";
			#clock-cells = <0x00>;
			clock-output-names = "core";
			clock-frequency = <0x2faf080>;
			phandle = <0x44>;
		};

		clksrc_mipi0_dsi_byteclk {
			compatible = "fixed-clock";
			#clock-cells = <0x00>;
			clock-output-names = "clksrc_mipi0_dsi_byteclk";
			clock-frequency = <0x44aa200>;
			phandle = <0x4d>;
		};

		clksrc_mipi1_dsi_byteclk {
			compatible = "fixed-clock";
			#clock-cells = <0x00>;
			clock-output-names = "clksrc_mipi1_dsi_byteclk";
			clock-frequency = <0x44aa200>;
			phandle = <0x4e>;
		};

		clksrc_gp0 {
			status = "disabled";
			compatible = "fixed-factor-clock";
			#clock-cells = <0x00>;
			clock-div = <0x01>;
			clock-mult = <0x01>;
			clocks = <0x30 0x21>;
			clock-output-names = "clksrc_gp0";
			phandle = <0x101>;
		};

		clksrc_gp1 {
			status = "disabled";
			compatible = "fixed-factor-clock";
			#clock-cells = <0x00>;
			clock-div = <0x01>;
			clock-mult = <0x01>;
			clocks = <0x30 0x22>;
			clock-output-names = "clksrc_gp1";
			phandle = <0x102>;
		};

		clksrc_gp2 {
			status = "disabled";
			compatible = "fixed-factor-clock";
			clock-div = <0x01>;
			clock-mult = <0x01>;
			#clock-cells = <0x00>;
			clocks = <0x30 0x23>;
			clock-output-names = "clksrc_gp2";
			phandle = <0x103>;
		};

		clksrc_gp3 {
			status = "disabled";
			compatible = "fixed-factor-clock";
			clock-div = <0x01>;
			clock-mult = <0x01>;
			#clock-cells = <0x00>;
			clocks = <0x30 0x24>;
			clock-output-names = "clksrc_gp3";
			phandle = <0x104>;
		};

		clksrc_gp4 {
			status = "disabled";
			compatible = "fixed-factor-clock";
			#clock-cells = <0x00>;
			clock-div = <0x01>;
			clock-mult = <0x01>;
			clocks = <0x30 0x25>;
			clock-output-names = "clksrc_gp4";
			phandle = <0x105>;
		};

		clksrc_gp5 {
			status = "disabled";
			compatible = "fixed-factor-clock";
			#clock-cells = <0x00>;
			clock-div = <0x01>;
			clock-mult = <0x01>;
			clocks = <0x30 0x26>;
			clock-output-names = "clksrc_gp5";
			phandle = <0x106>;
		};
	};

	phy {
		compatible = "usb-nop-xceiv";
		#phy-cells = <0x00>;
		phandle = <0x50>;
	};

	memory@0 {
		device_type = "memory";
		reg = <0x00 0x00 0x28000000>;
	};

	leds {
		compatible = "gpio-leds";
		phandle = <0x107>;

		led-pwr {
			label = "PWR";
			gpios = <0x35 0x2c 0x01>;
			default-state = "off";
			linux,default-trigger = "none";
			phandle = <0x6d>;
		};

		led-act {
			label = "ACT";
			gpios = <0x58 0x09 0x01>;
			default-state = "off";
			linux,default-trigger = "mmc0";
			phandle = <0x6c>;
		};
	};

	sd_io_1v8_reg {
		compatible = "regulator-gpio";
		regulator-name = "vdd-sd-io";
		regulator-min-microvolt = <0x1b7740>;
		regulator-max-microvolt = <0x325aa0>;
		regulator-boot-on;
		regulator-always-on;
		regulator-settling-time-us = <0x1388>;
		gpios = <0x58 0x03 0x00>;
		states = <0x1b7740 0x01 0x325aa0 0x00>;
		status = "okay";
		phandle = <0x56>;
	};

	sd_vcc_reg {
		compatible = "regulator-fixed";
		regulator-name = "vcc-sd";
		regulator-min-microvolt = <0x325aa0>;
		regulator-max-microvolt = <0x325aa0>;
		regulator-boot-on;
		enable-active-high;
		gpios = <0x58 0x04 0x00>;
		status = "okay";
		phandle = <0x57>;
	};

	wl_on_reg {
		compatible = "regulator-fixed";
		regulator-name = "wl-on-regulator";
		regulator-min-microvolt = <0x325aa0>;
		regulator-max-microvolt = <0x325aa0>;
		pinctrl-0 = <0x5c>;
		pinctrl-names = "default";
		gpio = <0x11 0x1c 0x00>;
		startup-delay-us = <0x249f0>;
		enable-active-high;
		phandle = <0x5a>;
	};

	cam1_clk {
		compatible = "fixed-clock";
		#clock-cells = <0x00>;
		status = "disabled";
		phandle = <0x108>;
	};

	cam0_clk {
		compatible = "fixed-clock";
		#clock-cells = <0x00>;
		status = "disabled";
		phandle = <0x109>;
	};

	cam0_reg {
		compatible = "regulator-fixed";
		regulator-name = "cam0_reg";
		enable-active-high;
		status = "okay";
		gpio = <0x35 0x22 0x00>;
		phandle = <0x10a>;
	};

	cam1_reg {
		compatible = "regulator-fixed";
		regulator-name = "cam1_reg";
		enable-active-high;
		status = "okay";
		gpio = <0x35 0x2e 0x00>;
		phandle = <0x10b>;
	};

	cam_dummy_reg {
		compatible = "regulator-fixed";
		regulator-name = "cam-dummy-reg";
		status = "okay";
		phandle = <0x10c>;
	};

	dummy {
		phandle = <0x10d>;
	};

	i2c0if {
		phandle = <0x10e>;
	};

	i2c0mux {
		phandle = <0x10f>;
	};

	rp1_vdd_3v3 {
		compatible = "regulator-fixed";
		regulator-name = "vdd-3v3";
		regulator-min-microvolt = <0x325aa0>;
		regulator-max-microvolt = <0x325aa0>;
		regulator-always-on;
		phandle = <0x45>;
	};

	__overrides__ {
		arm_freq;
		axiperf = "\0\0\0]status";
		bdaddr = "\0\0\0^local-bd-address[";
		button_debounce = "\0\0\0_debounce-interval:0";
		cooling_fan = [00 00 00 04 73 74 61 74 75 73 00 00 00 00 60 73 74 61 74 75 73 00];
		uart0_console = "\0\0\0astatus\0\0\0\0bconsole=\0/axi/pcie@120000/rp1/serial@30000";
		i2c0 = "\0\0\0cstatus";
		i2c1 = "\0\0\0dstatus";
		i2c = "\0\0\0dstatus";
		i2c_arm = "\0\0\0dstatus";
		i2c_vc = "\0\0\0cstatus";
		i2c_csi_dsi = "\0\0\0estatus";
		i2c_csi_dsi0 = "\0\0\0fstatus";
		i2c_csi_dsi1 = "\0\0\0estatus";
		i2c0_baudrate = "\0\0\0cclock-frequency:0";
		i2c1_baudrate = "\0\0\0dclock-frequency:0";
		i2c_baudrate = "\0\0\0dclock-frequency:0";
		i2c_arm_baudrate = "\0\0\0dclock-frequency:0";
		i2c_vc_baudrate = "\0\0\0cclock-frequency:0";
		krnbt = "\0\0\0^status";
		nvme = "\0\0\0gstatus";
		pciex1 = "\0\0\0gstatus";
		pciex1_gen = "\0\0\0gmax-link-speed:0";
		pciex1_no_l0s = "\0\0\0gaspm-no-l0s?";
		pciex1_tperst_clk_ms = "\0\0\0gbrcm,tperst-clk-ms:0";
		pcie_tperst_clk_ms = "\0\0\0gbrcm,tperst-clk-ms:0";
		random = "\0\0\0hstatus";
		rtc = "\0\0\0istatus";
		rtc_bbat_vchg = "\0\0\0itrickle-charge-microvolt:0";
		spi = "\0\0\0jstatus";
		suspend = "\0\0\0_linux,code:0=205";
		uart0 = "\0\0\0astatus";
		wifiaddr = "\0\0\0klocal-mac-address[";
		act_led_gpio = [00 00 00 6c 67 70 69 6f 73 3a 34 00 00 00 00 6c 67 70 69 6f 73 3a 30 3d 00 00 00 00 35];
		act_led_activelow = "\0\0\0lgpios:8";
		act_led_trigger = "\0\0\0llinux,default-trigger";
		pwr_led_gpio = "\0\0\0mgpios:4";
		pwr_led_activelow = "\0\0\0mgpios:8";
		pwr_led_trigger = "\0\0\0mlinux,default-trigger";
		eth_led0 = "\0\0\0Hled-modes:0";
		eth_led1 = "\0\0\0Hled-modes:4";
		drm_fb0_rp1_dsi0 = "\0\0\0bdrm-fb0=\0/axi/pcie@120000/rp1/dsi@110000";
		drm_fb0_rp1_dsi1 = "\0\0\0bdrm-fb0=\0/axi/pcie@120000/rp1/dsi@128000";
		drm_fb0_rp1_dpi = "\0\0\0bdrm-fb0=\0/axi/pcie@120000/rp1/dpi@148000";
		drm_fb0_vc4 = "\0\0\0bdrm-fb0=\0/axi/gpu";
		drm_fb1_rp1_dsi0 = "\0\0\0bdrm-fb1=\0/axi/pcie@120000/rp1/dsi@110000";
		drm_fb1_rp1_dsi1 = "\0\0\0bdrm-fb1=\0/axi/pcie@120000/rp1/dsi@128000";
		drm_fb1_rp1_dpi = "\0\0\0bdrm-fb1=\0/axi/pcie@120000/rp1/dpi@148000";
		drm_fb1_vc4 = "\0\0\0bdrm-fb1=\0/axi/gpu";
		drm_fb2_rp1_dsi0 = "\0\0\0bdrm-fb2=\0/axi/pcie@120000/rp1/dsi@110000";
		drm_fb2_rp1_dsi1 = "\0\0\0bdrm-fb2=\0/axi/pcie@120000/rp1/dsi@128000";
		drm_fb2_rp1_dpi = "\0\0\0bdrm-fb2=\0/axi/pcie@120000/rp1/dpi@148000";
		drm_fb2_vc4 = "\0\0\0bdrm-fb2=\0/axi/gpu";
		fan_temp0 = [00 00 00 03 74 65 6d 70 65 72 61 74 75 72 65 3a 30 00];
		fan_temp1 = [00 00 00 05 74 65 6d 70 65 72 61 74 75 72 65 3a 30 00];
		fan_temp2 = [00 00 00 06 74 65 6d 70 65 72 61 74 75 72 65 3a 30 00];
		fan_temp3 = "\0\0\0\atemperature:0";
		fan_temp0_hyst = [00 00 00 03 68 79 73 74 65 72 65 73 69 73 3a 30 00];
		fan_temp1_hyst = [00 00 00 05 68 79 73 74 65 72 65 73 69 73 3a 30 00];
		fan_temp2_hyst = [00 00 00 06 68 79 73 74 65 72 65 73 69 73 3a 30 00];
		fan_temp3_hyst = "\0\0\0\ahysteresis:0";
		fan_temp0_speed = [00 00 00 04 63 6f 6f 6c 69 6e 67 2d 6c 65 76 65 6c 73 3a 34 00];
		fan_temp1_speed = [00 00 00 04 63 6f 6f 6c 69 6e 67 2d 6c 65 76 65 6c 73 3a 38 00];
		fan_temp2_speed = [00 00 00 04 63 6f 6f 6c 69 6e 67 2d 6c 65 76 65 6c 73 3a 31 32 00];
		fan_temp3_speed = [00 00 00 04 63 6f 6f 6c 69 6e 67 2d 6c 65 76 65 6c 73 3a 31 36 00];
	};

	chosen {
		bootargs = "reboot=w coherent_pool=1M 8250.nr_uarts=1 pci=pcie_bus_safe snd_bcm2835.enable_compat_alsa=0 snd_bcm2835.enable_hdmi=1";
		stdout-path = "serial10:115200n8";
		phandle = <0x110>;
	};

	cooling_fan {
		status = "disabled";
		compatible = "pwm-fan";
		#cooling-cells = <0x02>;
		cooling-min-state = <0x00>;
		cooling-max-state = <0x03>;
		cooling-levels = <0x00 0x4b 0x7d 0xaf 0xfa>;
		pwms = <0x60 0x03 0xa25e 0x01>;
		rpm-regmap = <0x60>;
		rpm-offset = <0x3c>;
		phandle = <0x04>;
	};

	pwr_button {
		compatible = "gpio-keys";
		pinctrl-names = "default";
		pinctrl-0 = <0x6e>;
		status = "okay";

		pwr {
			label = "pwr_button";
			linux,code = <0x74>;
			gpios = <0x11 0x14 0x01>;
			debounce-interval = <0x32>;
			phandle = <0x5f>;
		};
	};

	aliases {
		blconfig = "/reserved-memory/nvram@0";
		bluetooth = "/soc/serial@7d50c000/bluetooth";
		console = "/soc/serial@7d001000";
		ethernet0 = "/axi/pcie@120000/rp1/ethernet@100000";
		wifi0 = "/axi/mmc@1100000/wifi@1";
		fb = "/soc/fb";
		mailbox = "/soc/mailbox@7c013880";
		mmc0 = "/axi/mmc@fff000";
		uart0 = "/axi/pcie@120000/rp1/serial@30000";
		uart1 = "/axi/pcie@120000/rp1/serial@34000";
		uart2 = "/axi/pcie@120000/rp1/serial@38000";
		uart3 = "/axi/pcie@120000/rp1/serial@3c000";
		uart4 = "/axi/pcie@120000/rp1/serial@40000";
		uart10 = "/soc/serial@7d001000";
		serial0 = "/axi/pcie@120000/rp1/serial@30000";
		serial1 = "/axi/pcie@120000/rp1/serial@34000";
		serial2 = "/axi/pcie@120000/rp1/serial@38000";
		serial3 = "/axi/pcie@120000/rp1/serial@3c000";
		serial4 = "/axi/pcie@120000/rp1/serial@40000";
		serial10 = "/soc/serial@7d001000";
		i2c = "/axi/pcie@120000/rp1/i2c@74000";
		i2c0 = "/axi/pcie@120000/rp1/i2c@70000";
		i2c1 = "/axi/pcie@120000/rp1/i2c@74000";
		i2c2 = "/axi/pcie@120000/rp1/i2c@78000";
		i2c3 = "/axi/pcie@120000/rp1/i2c@7c000";
		i2c4 = "/axi/pcie@120000/rp1/i2c@80000";
		i2c5 = "/axi/pcie@120000/rp1/i2c@84000";
		i2c6 = "/axi/pcie@120000/rp1/i2c@88000";
		i2c10 = "/soc/i2c@7d005600";
		spi0 = "/axi/pcie@120000/rp1/spi@50000";
		spi1 = "/axi/pcie@120000/rp1/spi@54000";
		spi2 = "/axi/pcie@120000/rp1/spi@58000";
		spi3 = "/axi/pcie@120000/rp1/spi@5c000";
		spi4 = "/axi/pcie@120000/rp1/spi@60000";
		spi5 = "/axi/pcie@120000/rp1/spi@64000";
		spi10 = "/soc/spi@7d004000";
		gpio0 = "/axi/pcie@120000/rp1/gpio@d0000";
		gpio1 = "/soc/gpio@7d508500";
		gpio2 = "/soc/gpio@7d517c00";
		gpio3 = "/soc/pinctrl@7d504100";
		gpio4 = "/soc/pinctrl@7d510700";
		usb0 = "/axi/pcie@120000/rp1/usb@200000";
		usb1 = "/axi/pcie@120000/rp1/usb@300000";
		drm-dsi1 = "/axi/pcie@120000/rp1/dsi@110000";
		drm-dsi2 = "/axi/pcie@120000/rp1/dsi@128000";
		phandle = <0x62>;
	};

	__symbols__ {
		rmem = "/reserved-memory";
		cma = "/reserved-memory/linux,cma";
		blconfig = "/reserved-memory/nvram@0";
		cpu_thermal = "/thermal-zones/cpu-thermal";
		thermal_trips = "/thermal-zones/cpu-thermal/trips";
		cpu_crit = "/thermal-zones/cpu-thermal/trips/cpu-crit";
		cpu_tepid = "/thermal-zones/cpu-thermal/trips/cpu-tepid";
		cpu_warm = "/thermal-zones/cpu-thermal/trips/cpu-warm";
		cpu_hot = "/thermal-zones/cpu-thermal/trips/cpu-hot";
		cpu_vhot = "/thermal-zones/cpu-thermal/trips/cpu-vhot";
		cooling_maps = "/thermal-zones/cpu-thermal/cooling-maps";
		clk_27MHz = "/clk-27M";
		clk_108MHz = "/clk-108M";
		hvs = "/hvs@107c580000";
		soc = "/soc";
		system_timer = "/soc/timer@7c003000";
		firmwarekms = "/soc/firmwarekms@7d503000";
		axiperf = "/soc/axiperf";
		mailbox = "/soc/mailbox@7c013880";
		pixelvalve0 = "/soc/pixelvalve@7c410000";
		pixelvalve1 = "/soc/pixelvalve@7c411000";
		mop = "/soc/mop@7c500000";
		moplet = "/soc/moplet@7c501000";
		disp_intr = "/soc/interrupt-controller@7c502000";
		dvp = "/soc/clock@7c700000";
		local_intc = "/soc/local_intc@7cd00000";
		uart10 = "/soc/serial@7d001000";
		_uart0 = "/soc/serial@7d001000";
		_uart2 = "/soc/serial@7d001400";
		_uart5 = "/soc/serial@7d001a00";
		sdhost = "/soc/mmc@7d002000";
		_i2s = "/soc/_i2s@7d003000";
		spi10 = "/soc/spi@7d004000";
		_spi0 = "/soc/spi@7d004000";
		spidev10 = "/soc/spi@7d004000/spidev@0";
		_spi3 = "/soc/spi@7d004600";
		_spi4 = "/soc/spi@7d004800";
		_spi5 = "/soc/spi@7d004a00";
		_spi6 = "/soc/spi@7d004c00";
		_i2c0 = "/soc/i2c@7d005000";
		i2c_rp1boot = "/soc/i2c@7d005600";
		_i2c3 = "/soc/i2c@7d005600";
		_i2c4 = "/soc/i2c@7d005800";
		_i2c5 = "/soc/i2c@7d005a00";
		_i2c6 = "/soc/i2c@7d005c00";
		_i2c8 = "/soc/i2c@7d005e00";
		_pwm0 = "/soc/pwm@7d00c000";
		_pwm1 = "/soc/pwm@7d00c800";
		pm = "/soc/watchdog@7d200000";
		cprman = "/soc/cprman@7d202000";
		random = "/soc/rng@7d208000";
		cpu_l2_irq = "/soc/intc@7d503000";
		pinctrl = "/soc/pinctrl@7d504100";
		uarta_24_pins = "/soc/pinctrl@7d504100/uarta_24_pins";
		sdio2_30_pins = "/soc/pinctrl@7d504100/sdio2_30_pins";
		pwr_button_pins = "/soc/pinctrl@7d504100/pwr_button_pins";
		wl_on_pins = "/soc/pinctrl@7d504100/wl_on_pins";
		bt_shutdown_pins = "/soc/pinctrl@7d504100/bt_shutdown_pins";
		emmc_sd_pulls = "/soc/pinctrl@7d504100/emmc_sd_pulls";
		spi10_pins = "/soc/pinctrl@7d504100/spi10_gpio2";
		spi10_gpio2 = "/soc/pinctrl@7d504100/spi10_gpio2";
		spi10_cs_pins = "/soc/pinctrl@7d504100/spi10_cs_gpio1";
		spi10_cs_gpio1 = "/soc/pinctrl@7d504100/spi10_cs_gpio1";
		ddc0 = "/soc/i2c@7d508200";
		ddc1 = "/soc/i2c@7d508280";
		bscd = "/soc/i2c@7d508300";
		bsc_irq = "/soc/intc@7d508380";
		main_irq = "/soc/intc@7d508400";
		gio = "/soc/gpio@7d508500";
		uarta = "/soc/serial@7d50c000";
		bluetooth = "/soc/serial@7d50c000/bluetooth";
		uartb = "/soc/serial@7d50d000";
		aon_intr = "/soc/interrupt-controller@7d510600";
		pinctrl_aon = "/soc/pinctrl@7d510700";
		i2c3_m4_agpio0_pins = "/soc/pinctrl@7d510700/i2c3_m4_agpio0_pins";
		bsc_m1_agpio13_pins = "/soc/pinctrl@7d510700/bsc_m1_agpio13_pins";
		bsc_pmu_sgpio4_pins = "/soc/pinctrl@7d510700/bsc_pmu_sgpio4_pins";
		bsc_m2_sgpio4_pins = "/soc/pinctrl@7d510700/bsc_m2_sgpio4_pins";
		pwm_aon_agpio1_pins = "/soc/pinctrl@7d510700/pwm_aon_agpio1_pins";
		pwm_aon_agpio4_pins = "/soc/pinctrl@7d510700/pwm_aon_agpio4_pins";
		pwm_aon_agpio7_pins = "/soc/pinctrl@7d510700/pwm_aon_agpio7_pins";
		emmc_aon_cd_pins = "/soc/pinctrl@7d510700/emmc_aon_cd_pins";
		aon_pwm_1pin = "/soc/pinctrl@7d510700/aon_pwm_1pin";
		bscc = "/soc/i2c@7d517a00";
		pwm_aon = "/soc/pwm@7d517a80";
		main_aon_irq = "/soc/intc@7d517ac0";
		bsc_aon_irq = "/soc/intc@7d517b00";
		gio_aon = "/soc/gpio@7d517c00";
		avs_monitor = "/soc/avs-monitor@7d542000";
		thermal = "/soc/avs-monitor@7d542000/thermal";
		bsc_pmu = "/soc/i2c@7d544000";
		hdmi0 = "/soc/hdmi@7ef00700";
		hdmi1 = "/soc/hdmi@7ef05700";
		sound = "/soc/sound";
		firmware = "/soc/firmware";
		firmware_clocks = "/soc/firmware/clocks";
		reset = "/soc/firmware/reset";
		vcio = "/soc/firmware/vcio";
		power = "/soc/power";
		fb = "/soc/fb";
		rpi_rtc = "/soc/rpi_rtc";
		vdd_3v3_reg = "/soc/fixedregulator_3v3";
		vdd_5v0_reg = "/soc/fixedregulator_5v0";
		cpus = "/cpus";
		cpu0 = "/cpus/cpu@0";
		cpu1 = "/cpus/cpu@1";
		cpu2 = "/cpus/cpu@2";
		cpu3 = "/cpus/cpu@3";
		l2_cache = "/cpus/l2-cache";
		l3_cache = "/cpus/l3-cache";
		axi = "/axi";
		vc4 = "/axi/gpu";
		iommu2 = "/axi/iommu@5100";
		iommu4 = "/axi/iommu@5200";
		iommu5 = "/axi/iommu@5280";
		iommuc = "/axi/iommuc@5b00";
		dma32 = "/axi/dma@10000";
		dma40 = "/axi/dma@10600";
		pcie0 = "/axi/pcie@100000";
		pciex1 = "/axi/pcie@110000";
		pcie1 = "/axi/pcie@110000";
		pcie_rescal = "/axi/reset-controller@119500";
		pciex4 = "/axi/pcie@120000";
		rp1_target = "/axi/pcie@120000";
		pcie2 = "/axi/pcie@120000";
		rp1 = "/axi/pcie@120000/rp1";
		rp1_clocks = "/axi/pcie@120000/rp1/clocks@18000";
		uart0 = "/axi/pcie@120000/rp1/serial@30000";
		rp1_uart0 = "/axi/pcie@120000/rp1/serial@30000";
		uart1 = "/axi/pcie@120000/rp1/serial@34000";
		rp1_uart1 = "/axi/pcie@120000/rp1/serial@34000";
		uart2 = "/axi/pcie@120000/rp1/serial@38000";
		rp1_uart2 = "/axi/pcie@120000/rp1/serial@38000";
		uart3 = "/axi/pcie@120000/rp1/serial@3c000";
		rp1_uart3 = "/axi/pcie@120000/rp1/serial@3c000";
		uart4 = "/axi/pcie@120000/rp1/serial@40000";
		rp1_uart4 = "/axi/pcie@120000/rp1/serial@40000";
		rp1_uart5 = "/axi/pcie@120000/rp1/serial@44000";
		rp1_spi8 = "/axi/pcie@120000/rp1/spi@4c000";
		spi0 = "/axi/pcie@120000/rp1/spi@50000";
		rp1_spi0 = "/axi/pcie@120000/rp1/spi@50000";
		spidev0 = "/axi/pcie@120000/rp1/spi@50000/spidev@0";
		spidev1 = "/axi/pcie@120000/rp1/spi@50000/spidev@1";
		spi1 = "/axi/pcie@120000/rp1/spi@54000";
		rp1_spi1 = "/axi/pcie@120000/rp1/spi@54000";
		spi2 = "/axi/pcie@120000/rp1/spi@58000";
		rp1_spi2 = "/axi/pcie@120000/rp1/spi@58000";
		spi3 = "/axi/pcie@120000/rp1/spi@5c000";
		rp1_spi3 = "/axi/pcie@120000/rp1/spi@5c000";
		spi4 = "/axi/pcie@120000/rp1/spi@60000";
		rp1_spi4 = "/axi/pcie@120000/rp1/spi@60000";
		spi5 = "/axi/pcie@120000/rp1/spi@64000";
		rp1_spi5 = "/axi/pcie@120000/rp1/spi@64000";
		rp1_spi6 = "/axi/pcie@120000/rp1/spi@68000";
		rp1_spi7 = "/axi/pcie@120000/rp1/spi@6c000";
		i2c_vc = "/axi/pcie@120000/rp1/i2c@70000";
		i2c0 = "/axi/pcie@120000/rp1/i2c@70000";
		rp1_i2c0 = "/axi/pcie@120000/rp1/i2c@70000";
		i2c_arm = "/axi/pcie@120000/rp1/i2c@74000";
		i2c1 = "/axi/pcie@120000/rp1/i2c@74000";
		rp1_i2c1 = "/axi/pcie@120000/rp1/i2c@74000";
		i2c2 = "/axi/pcie@120000/rp1/i2c@78000";
		rp1_i2c2 = "/axi/pcie@120000/rp1/i2c@78000";
		i2c3 = "/axi/pcie@120000/rp1/i2c@7c000";
		rp1_i2c3 = "/axi/pcie@120000/rp1/i2c@7c000";
		i2c_csi_dsi = "/axi/pcie@120000/rp1/i2c@80000";
		i2c_csi_dsi1 = "/axi/pcie@120000/rp1/i2c@80000";
		i2c4 = "/axi/pcie@120000/rp1/i2c@80000";
		rp1_i2c4 = "/axi/pcie@120000/rp1/i2c@80000";
		i2c5 = "/axi/pcie@120000/rp1/i2c@84000";
		rp1_i2c5 = "/axi/pcie@120000/rp1/i2c@84000";
		i2c_csi_dsi0 = "/axi/pcie@120000/rp1/i2c@88000";
		i2c6 = "/axi/pcie@120000/rp1/i2c@88000";
		rp1_i2c6 = "/axi/pcie@120000/rp1/i2c@88000";
		pwm = "/axi/pcie@120000/rp1/pwm@98000";
		pwm0 = "/axi/pcie@120000/rp1/pwm@98000";
		rp1_pwm0 = "/axi/pcie@120000/rp1/pwm@98000";
		pwm1 = "/axi/pcie@120000/rp1/pwm@9c000";
		rp1_pwm1 = "/axi/pcie@120000/rp1/pwm@9c000";
		i2s_clk_producer = "/axi/pcie@120000/rp1/i2s@a0000";
		i2s = "/axi/pcie@120000/rp1/i2s@a0000";
		rp1_i2s0 = "/axi/pcie@120000/rp1/i2s@a0000";
		i2s_clk_consumer = "/axi/pcie@120000/rp1/i2s@a4000";
		rp1_i2s1 = "/axi/pcie@120000/rp1/i2s@a4000";
		rp1_i2s2 = "/axi/pcie@120000/rp1/i2s@a8000";
		rp1_sdio_clk0 = "/axi/pcie@120000/rp1/sdio_clk0@b0004";
		rp1_sdio_clk1 = "/axi/pcie@120000/rp1/sdio_clk1@b4004";
		rp1_adc = "/axi/pcie@120000/rp1/adc@c8000";
		gpio = "/axi/pcie@120000/rp1/gpio@d0000";
		rp1_gpio = "/axi/pcie@120000/rp1/gpio@d0000";
		uart0_pins = "/axi/pcie@120000/rp1/gpio@d0000/rp1_uart0_14_15";
		rp1_uart0_14_15 = "/axi/pcie@120000/rp1/gpio@d0000/rp1_uart0_14_15";
		uart0_ctsrts_pins = "/axi/pcie@120000/rp1/gpio@d0000/rp1_uart0_ctsrts_16_17";
		rp1_uart0_ctsrts_16_17 = "/axi/pcie@120000/rp1/gpio@d0000/rp1_uart0_ctsrts_16_17";
		uart1_pins = "/axi/pcie@120000/rp1/gpio@d0000/rp1_uart1_0_1";
		rp1_uart1_0_1 = "/axi/pcie@120000/rp1/gpio@d0000/rp1_uart1_0_1";
		uart1_ctsrts_pins = "/axi/pcie@120000/rp1/gpio@d0000/rp1_uart1_ctsrts_2_3";
		rp1_uart1_ctsrts_2_3 = "/axi/pcie@120000/rp1/gpio@d0000/rp1_uart1_ctsrts_2_3";
		uart2_pins = "/axi/pcie@120000/rp1/gpio@d0000/rp1_uart2_4_5";
		rp1_uart2_4_5 = "/axi/pcie@120000/rp1/gpio@d0000/rp1_uart2_4_5";
		uart2_ctsrts_pins = "/axi/pcie@120000/rp1/gpio@d0000/rp1_uart2_ctsrts_6_7";
		rp1_uart2_ctsrts_6_7 = "/axi/pcie@120000/rp1/gpio@d0000/rp1_uart2_ctsrts_6_7";
		uart3_pins = "/axi/pcie@120000/rp1/gpio@d0000/rp1_uart3_8_9";
		rp1_uart3_8_9 = "/axi/pcie@120000/rp1/gpio@d0000/rp1_uart3_8_9";
		uart3_ctsrts_pins = "/axi/pcie@120000/rp1/gpio@d0000/rp1_uart3_ctsrts_10_11";
		rp1_uart3_ctsrts_10_11 = "/axi/pcie@120000/rp1/gpio@d0000/rp1_uart3_ctsrts_10_11";
		uart4_pins = "/axi/pcie@120000/rp1/gpio@d0000/rp1_uart4_12_13";
		rp1_uart4_12_13 = "/axi/pcie@120000/rp1/gpio@d0000/rp1_uart4_12_13";
		uart4_ctsrts_pins = "/axi/pcie@120000/rp1/gpio@d0000/rp1_uart4_ctsrts_14_15";
		rp1_uart4_ctsrts_14_15 = "/axi/pcie@120000/rp1/gpio@d0000/rp1_uart4_ctsrts_14_15";
		rp1_sdio0_22_27 = "/axi/pcie@120000/rp1/gpio@d0000/rp1_sdio0_22_27";
		rp1_sdio1_28_33 = "/axi/pcie@120000/rp1/gpio@d0000/rp1_sdio1_28_33";
		rp1_i2s0_18_21 = "/axi/pcie@120000/rp1/gpio@d0000/rp1_i2s0_18_21";
		rp1_i2s1_18_21 = "/axi/pcie@120000/rp1/gpio@d0000/rp1_i2s1_18_21";
		rp1_i2c4_34_35 = "/axi/pcie@120000/rp1/gpio@d0000/rp1_i2c4_34_35";
		rp1_i2c6_38_39 = "/axi/pcie@120000/rp1/gpio@d0000/rp1_i2c6_38_39";
		rp1_i2c4_40_41 = "/axi/pcie@120000/rp1/gpio@d0000/rp1_i2c4_40_41";
		rp1_i2c5_44_45 = "/axi/pcie@120000/rp1/gpio@d0000/rp1_i2c5_44_45";
		rp1_i2c0_0_1 = "/axi/pcie@120000/rp1/gpio@d0000/rp1_i2c0_0_1";
		rp1_i2c0_8_9 = "/axi/pcie@120000/rp1/gpio@d0000/rp1_i2c0_8_9";
		rp1_i2c1_2_3 = "/axi/pcie@120000/rp1/gpio@d0000/rp1_i2c1_2_3";
		rp1_i2c1_10_11 = "/axi/pcie@120000/rp1/gpio@d0000/rp1_i2c1_10_11";
		rp1_i2c2_4_5 = "/axi/pcie@120000/rp1/gpio@d0000/rp1_i2c2_4_5";
		rp1_i2c2_12_13 = "/axi/pcie@120000/rp1/gpio@d0000/rp1_i2c2_12_13";
		rp1_i2c3_6_7 = "/axi/pcie@120000/rp1/gpio@d0000/rp1_i2c3_6_7";
		rp1_i2c3_14_15 = "/axi/pcie@120000/rp1/gpio@d0000/rp1_i2c3_14_15";
		rp1_i2c3_22_23 = "/axi/pcie@120000/rp1/gpio@d0000/rp1_i2c3_22_23";
		dpi_16bit_gpio2 = "/axi/pcie@120000/rp1/gpio@d0000/rp1_dpi_16bit_gpio2";
		rp1_dpi_16bit_gpio2 = "/axi/pcie@120000/rp1/gpio@d0000/rp1_dpi_16bit_gpio2";
		dpi_16bit_cpadhi_gpio2 = "/axi/pcie@120000/rp1/gpio@d0000/rp1_dpi_16bit_cpadhi_gpio2";
		rp1_dpi_16bit_cpadhi_gpio2 = "/axi/pcie@120000/rp1/gpio@d0000/rp1_dpi_16bit_cpadhi_gpio2";
		rp1_dpi_16bit_pad666_gpio2 = "/axi/pcie@120000/rp1/gpio@d0000/rp1_dpi_16bit_pad666_gpio2";
		dpi_18bit_gpio2 = "/axi/pcie@120000/rp1/gpio@d0000/rp1_dpi_18bit_gpio2";
		rp1_dpi_18bit_gpio2 = "/axi/pcie@120000/rp1/gpio@d0000/rp1_dpi_18bit_gpio2";
		dpi_18bit_cpadhi_gpio2 = "/axi/pcie@120000/rp1/gpio@d0000/rp1_dpi_18bit_cpadhi_gpio2";
		rp1_dpi_18bit_cpadhi_gpio2 = "/axi/pcie@120000/rp1/gpio@d0000/rp1_dpi_18bit_cpadhi_gpio2";
		dpi_gpio1 = "/axi/pcie@120000/rp1/gpio@d0000/rp1_dpi_24bit_gpio2";
		rp1_dpi_24bit_gpio2 = "/axi/pcie@120000/rp1/gpio@d0000/rp1_dpi_24bit_gpio2";
		rp1_dpi_hvsync = "/axi/pcie@120000/rp1/gpio@d0000/rp1_dpi_hvsync";
		dpi_16bit_gpio0 = "/axi/pcie@120000/rp1/gpio@d0000/rp1_dpi_16bit_gpio0";
		rp1_dpi_16bit_gpio0 = "/axi/pcie@120000/rp1/gpio@d0000/rp1_dpi_16bit_gpio0";
		dpi_16bit_cpadhi_gpio0 = "/axi/pcie@120000/rp1/gpio@d0000/rp1_dpi_16bit_cpadhi_gpio0";
		rp1_dpi_16bit_cpadhi_gpio0 = "/axi/pcie@120000/rp1/gpio@d0000/rp1_dpi_16bit_cpadhi_gpio0";
		rp1_dpi_16bit_pad666_gpio0 = "/axi/pcie@120000/rp1/gpio@d0000/rp1_dpi_16bit_pad666_gpio0";
		dpi_18bit_gpio0 = "/axi/pcie@120000/rp1/gpio@d0000/rp1_dpi_18bit_gpio0";
		rp1_dpi_18bit_gpio0 = "/axi/pcie@120000/rp1/gpio@d0000/rp1_dpi_18bit_gpio0";
		dpi_18bit_cpadhi_gpio0 = "/axi/pcie@120000/rp1/gpio@d0000/rp1_dpi_18bit_cpadhi_gpio0";
		rp1_dpi_18bit_cpadhi_gpio0 = "/axi/pcie@120000/rp1/gpio@d0000/rp1_dpi_18bit_cpadhi_gpio0";
		dpi_gpio0 = "/axi/pcie@120000/rp1/gpio@d0000/rp1_dpi_24bit_gpio0";
		rp1_dpi_24bit_gpio0 = "/axi/pcie@120000/rp1/gpio@d0000/rp1_dpi_24bit_gpio0";
		rp1_gpclksrc0_gpio4 = "/axi/pcie@120000/rp1/gpio@d0000/rp1_gpclksrc0_gpio4";
		rp1_gpclksrc0_gpio20 = "/axi/pcie@120000/rp1/gpio@d0000/rp1_gpclksrc0_gpio20";
		rp1_gpclksrc1_gpio5 = "/axi/pcie@120000/rp1/gpio@d0000/rp1_gpclksrc1_gpio5";
		rp1_gpclksrc1_gpio18 = "/axi/pcie@120000/rp1/gpio@d0000/rp1_gpclksrc1_gpio18";
		rp1_gpclksrc1_gpio21 = "/axi/pcie@120000/rp1/gpio@d0000/rp1_gpclksrc1_gpio21";
		rp1_pwm1_gpio45 = "/axi/pcie@120000/rp1/gpio@d0000/rp1_pwm1_gpio45";
		spi0_pins = "/axi/pcie@120000/rp1/gpio@d0000/rp1_spi0_gpio9";
		rp1_spi0_gpio9 = "/axi/pcie@120000/rp1/gpio@d0000/rp1_spi0_gpio9";
		spi0_cs_pins = "/axi/pcie@120000/rp1/gpio@d0000/rp1_spi0_cs_gpio7";
		rp1_spi0_cs_gpio7 = "/axi/pcie@120000/rp1/gpio@d0000/rp1_spi0_cs_gpio7";
		rp1_spi1_gpio19 = "/axi/pcie@120000/rp1/gpio@d0000/rp1_spi1_gpio19";
		spi2_pins = "/axi/pcie@120000/rp1/gpio@d0000/rp1_spi2_gpio1";
		rp1_spi2_gpio1 = "/axi/pcie@120000/rp1/gpio@d0000/rp1_spi2_gpio1";
		spi3_pins = "/axi/pcie@120000/rp1/gpio@d0000/rp1_spi3_gpio5";
		rp1_spi3_gpio5 = "/axi/pcie@120000/rp1/gpio@d0000/rp1_spi3_gpio5";
		spi4_pins = "/axi/pcie@120000/rp1/gpio@d0000/rp1_spi4_gpio9";
		rp1_spi4_gpio9 = "/axi/pcie@120000/rp1/gpio@d0000/rp1_spi4_gpio9";
		spi5_pins = "/axi/pcie@120000/rp1/gpio@d0000/rp1_spi5_gpio13";
		rp1_spi5_gpio13 = "/axi/pcie@120000/rp1/gpio@d0000/rp1_spi5_gpio13";
		rp1_spi8_gpio49 = "/axi/pcie@120000/rp1/gpio@d0000/rp1_spi8_gpio49";
		rp1_spi8_cs_gpio52 = "/axi/pcie@120000/rp1/gpio@d0000/rp1_spi8_cs_gpio52";
		usb_vbus_pins = "/axi/pcie@120000/rp1/gpio@d0000/usb_vbus_pins";
		rp1_eth = "/axi/pcie@120000/rp1/ethernet@100000";
		phy1 = "/axi/pcie@120000/rp1/ethernet@100000/ethernet-phy@1";
		csi0 = "/axi/pcie@120000/rp1/csi@110000";
		rp1_csi0 = "/axi/pcie@120000/rp1/csi@110000";
		csi1 = "/axi/pcie@120000/rp1/csi@128000";
		rp1_csi1 = "/axi/pcie@120000/rp1/csi@128000";
		rp1_mmc0 = "/axi/pcie@120000/rp1/mmc@180000";
		rp1_mmc1 = "/axi/pcie@120000/rp1/mmc@184000";
		rp1_dma = "/axi/pcie@120000/rp1/dma@188000";
		rp1_usb0 = "/axi/pcie@120000/rp1/usb@200000";
		rp1_usb1 = "/axi/pcie@120000/rp1/usb@300000";
		dsi0 = "/axi/pcie@120000/rp1/dsi@110000";
		rp1_dsi0 = "/axi/pcie@120000/rp1/dsi@110000";
		dsi1 = "/axi/pcie@120000/rp1/dsi@128000";
		rp1_dsi1 = "/axi/pcie@120000/rp1/dsi@128000";
		vec = "/axi/pcie@120000/rp1/vec@144000";
		rp1_vec = "/axi/pcie@120000/rp1/vec@144000";
		dpi = "/axi/pcie@120000/rp1/dpi@148000";
		rp1_dpi = "/axi/pcie@120000/rp1/dpi@148000";
		mip0 = "/axi/msi-controller@130000";
		mip1 = "/axi/msi-controller@131000";
		syscon_piarbctl = "/axi/syscon@400018";
		usb = "/axi/usb@480000";
		rpivid = "/axi/codec@800000";
		sdio1 = "/axi/mmc@fff000";
		sdio2 = "/axi/mmc@1100000";
		wifi = "/axi/mmc@1100000/wifi@1";
		bcm_reset = "/axi/reset-controller@1504318";
		v3d = "/axi/v3d@2000000";
		gicv2 = "/axi/interrupt-controller@7fff9000";
		pisp_be = "/axi/pisp_be@880000";
		clocks = "/clocks";
		clk_osc = "/clocks/clk-osc";
		clk_usb = "/clocks/clk-usb";
		clk_vpu = "/clocks/clk_vpu";
		clk_uart = "/clocks/clk_uart";
		clk_emmc2 = "/clocks/clk_emmc2";
		clk_xosc = "/clocks/clk_xosc";
		macb_pclk = "/clocks/macb_pclk";
		macb_hclk = "/clocks/macb_hclk";
		sdio_src = "/clocks/sdio_src";
		sdhci_core = "/clocks/sdhci_core";
		clksrc_mipi0_dsi_byteclk = "/clocks/clksrc_mipi0_dsi_byteclk";
		clksrc_mipi1_dsi_byteclk = "/clocks/clksrc_mipi1_dsi_byteclk";
		clksrc_gp0 = "/clocks/clksrc_gp0";
		clksrc_gp1 = "/clocks/clksrc_gp1";
		clksrc_gp2 = "/clocks/clksrc_gp2";
		clksrc_gp3 = "/clocks/clksrc_gp3";
		clksrc_gp4 = "/clocks/clksrc_gp4";
		clksrc_gp5 = "/clocks/clksrc_gp5";
		usbphy = "/phy";
		leds = "/leds";
		led_pwr = "/leds/led-pwr";
		led_act = "/leds/led-act";
		sd_io_1v8_reg = "/sd_io_1v8_reg";
		sd_vcc_reg = "/sd_vcc_reg";
		wl_on_reg = "/wl_on_reg";
		cam1_clk = "/cam1_clk";
		cam0_clk = "/cam0_clk";
		cam0_reg = "/cam0_reg";
		cam1_reg = "/cam1_reg";
		cam_dummy_reg = "/cam_dummy_reg";
		aux = "/dummy";
		dummy = "/dummy";
		i2c0if = "/i2c0if";
		i2c0mux = "/i2c0mux";
		rp1_vdd_3v3 = "/rp1_vdd_3v3";
		chosen = "/chosen";
		fan = "/cooling_fan";
		pwr_key = "/pwr_button/pwr";
		aliases = "/aliases";
	};
};
